VERSION ""

NS_ :

BS_:

BU_:

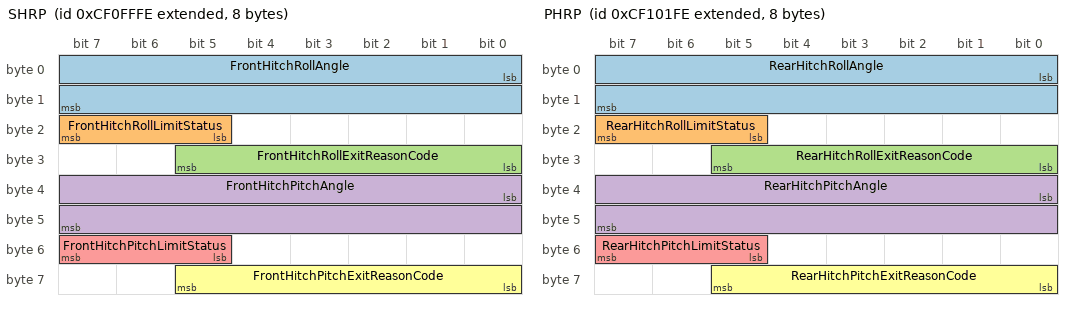
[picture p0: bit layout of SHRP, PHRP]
BO_ 2364604414 SHRP: 8 Vector__XXX
 SG_ FrontHitchRollAngle : 0|16@1+ (0.002,-64) [-64|64.51] "deg" Vector__XXX
 SG_ FrontHitchRollLimitStatus : 21|3@1+ (1,0) [0|7] "" Vector__XXX
 SG_ FrontHitchRollExitReasonCode : 24|6@1+ (1,0) [0|63] "" Vector__XXX
 SG_ FrontHitchPitchAngle : 32|16@1+ (0.002,-64) [-64|64.51] "deg" Vector__XXX
 SG_ FrontHitchPitchLimitStatus : 53|3@1+ (1,0) [0|7] "" Vector__XXX
 SG_ FrontHitchPitchExitReasonCode : 56|6@1+ (1,0) [0|63] "" Vector__XXX

BO_ 2364604926 PHRP: 8 Vector__XXX
 SG_ RearHitchRollAngle : 0|16@1+ (0.002,-64) [-64|64.51] "deg" Vector__XXX
 SG_ RearHitchRollLimitStatus : 21|3@1+ (1,0) [0|7] "" Vector__XXX
 SG_ RearHitchRollExitReasonCode : 24|6@1+ (1,0) [0|63] "" Vector__XXX
 SG_ RearHitchPitchAngle : 32|16@1+ (0.002,-64) [-64|64.51] "deg" Vector__XXX
 SG_ RearHitchPitchLimitStatus : 53|3@1+ (1,0) [0|7] "" Vector__XXX
 SG_ RearHitchPitchExitReasonCode : 56|6@1+ (1,0) [0|63] "" Vector__XXX

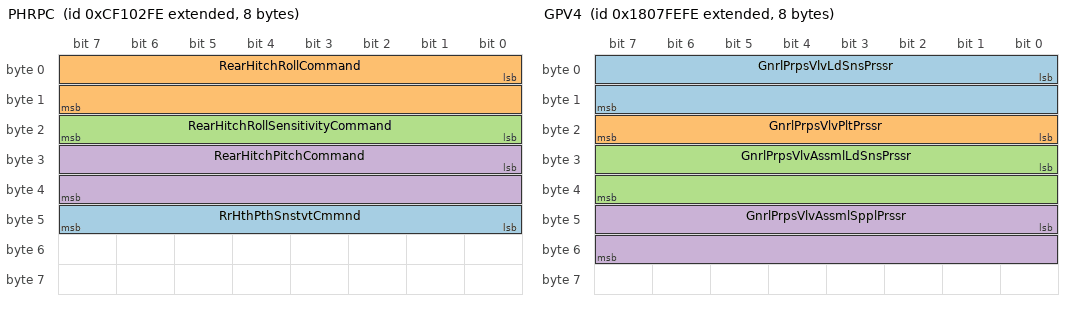
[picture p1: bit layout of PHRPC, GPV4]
BO_ 2364605182 PHRPC: 8 Vector__XXX
 SG_ RrHthPthSnstvtCmmnd : 40|8@1+ (0.4,0) [0|100] "%" Vector__XXX
 SG_ RearHitchRollCommand : 0|16@1+ (0.002,-64) [-64|64.51] "deg" Vector__XXX
 SG_ RearHitchRollSensitivityCommand : 16|8@1+ (0.4,0) [0|100] "%" Vector__XXX
 SG_ RearHitchPitchCommand : 24|16@1+ (0.002,-64) [-64|64.51] "deg" Vector__XXX

BO_ 2365473278 LCMD: 8 Vector__XXX
 SG_ ImplementOemOption1LightCommand : 50|2@1+ (1,0) [0|3] "" Vector__XXX
 SG_ ImplementOemOption2LightCommand : 48|2@1+ (1,0) [0|3] "" Vector__XXX
 SG_ RotatingBeaconLightCommand : 10|2@1+ (1,0) [0|3] "" Vector__XXX
 SG_ TractorFrontFogLightsCommand : 8|2@1+ (1,0) [0|3] "" Vector__XXX
 SG_ TrtrFrntHghMntdWrkLghtsCmmnd : 46|2@1+ (1,0) [0|3] "" Vector__XXX
 SG_ TrtrFrntLwMntdWrkLghtsCmmnd : 44|2@1+ (1,0) [0|3] "" Vector__XXX
 SG_ TrtrUndrsdMntdWrkLghtsCmmnd : 34|2@1+ (1,0) [0|3] "" Vector__XXX
 SG_ DaytimeRunningLightsCommand : 0|2@1+ (1,0) [0|3] "" Vector__XXX
 SG_ AlternateHeadlightsCommand : 2|2@1+ (1,0) [0|3] "" Vector__XXX
 SG_ LowBeamHeadlightsCommand : 4|2@1+ (1,0) [0|3] "" Vector__XXX
 SG_ HighBeamHeadlightsCommand : 6|2@1+ (1,0) [0|3] "" Vector__XXX
 SG_ RightTurnSignalLightsCommand : 12|2@1+ (1,0) [0|3] "" Vector__XXX
 SG_ LeftTurnSignalLightsCommand : 14|2@1+ (1,0) [0|3] "" Vector__XXX
 SG_ BackUpLightsAndAlarmHornCommand : 16|2@1+ (1,0) [0|3] "" Vector__XXX
 SG_ CentreStopLightsCommand : 18|2@1+ (1,0) [0|3] "" Vector__XXX
 SG_ RightStopLightsCommand : 20|2@1+ (1,0) [0|3] "" Vector__XXX
 SG_ LeftStopLightsCommand : 22|2@1+ (1,0) [0|3] "" Vector__XXX
 SG_ ImplementClearanceLightsCommand : 24|2@1+ (1,0) [0|3] "" Vector__XXX
 SG_ TractorClearanceLightsCommand : 26|2@1+ (1,0) [0|3] "" Vector__XXX
 SG_ ImplmntMrkrPstnLghtsCmmnd : 28|2@1+ (1,0) [0|3] "" Vector__XXX
 SG_ TrtrMrkrPstnLghtsCmmnd : 30|2@1+ (1,0) [0|3] "" Vector__XXX
 SG_ RearFogLightsCommand : 32|2@1+ (1,0) [0|3] "" Vector__XXX
 SG_ TrtrRrLwMntdWrkLghtsCmmnd : 36|2@1+ (1,0) [0|3] "" Vector__XXX
 SG_ TrtrRrHghMntdWrkLghtsCmmnd : 38|2@1+ (1,0) [0|3] "" Vector__XXX
 SG_ TrtrSdLwMntdWrkLghtsCmmnd : 40|2@1+ (1,0) [0|3] "" Vector__XXX
 SG_ TrtrSdHghMntdWrkLghtsCmmnd : 42|2@1+ (1,0) [0|3] "" Vector__XXX
 SG_ ImplmntRghtFrwrdWrkLghtsCmmnd : 52|2@1+ (1,0) [0|3] "" Vector__XXX
 SG_ ImplmntLftFrwrdWrkLghtsCmmnd : 54|2@1+ (1,0) [0|3] "" Vector__XXX
 SG_ LghtngDtMssgRqstCmmnd : 56|2@1+ (1,0) [0|3] "" Vector__XXX
 SG_ ImplmntRghtFngWrkLghtsCmmnd : 58|2@1+ (1,0) [0|3] "" Vector__XXX
 SG_ ImplmntLftFngWrkLghtsCmmnd : 60|2@1+ (1,0) [0|3] "" Vector__XXX
 SG_ ImplementRearWorkLightsCommand : 62|2@1+ (1,0) [0|3] "" Vector__XXX

BO_ 2550660862 GPV4: 8 Vector__XXX
 SG_ GnrlPrpsVlvLdSnsPrssr : 0|16@1+ (5,0) [0|321275] "kPa" Vector__XXX
 SG_ GnrlPrpsVlvPltPrssr : 16|8@1+ (16,0) [0|4000] "kPa" Vector__XXX
 SG_ GnrlPrpsVlvAssmlLdSnsPrssr : 24|16@1+ (5,0) [0|321275] "kPa" Vector__XXX
 SG_ GnrlPrpsVlvAssmlSpplPrssr : 40|16@1+ (5,0) [0|321275] "kPa" Vector__XXX

BO_ 2566655742 PHRPS: 8 Vector__XXX
 SG_ RearHitchPitchSensitivity : 8|8@1+ (0.4,0) [0|100] "%" Vector__XXX
 SG_ RearHitchRollSensitivity : 0|8@1+ (0.4,0) [0|100] "%" Vector__XXX

BO_ 2566655998 SHRPS: 8 Vector__XXX
 SG_ FrontHitchRollSensitivity : 0|8@1+ (0.4,0) [0|100] "%" Vector__XXX
 SG_ FrontHitchPitchSensitivity : 8|8@1+ (0.4,0) [0|100] "%" Vector__XXX

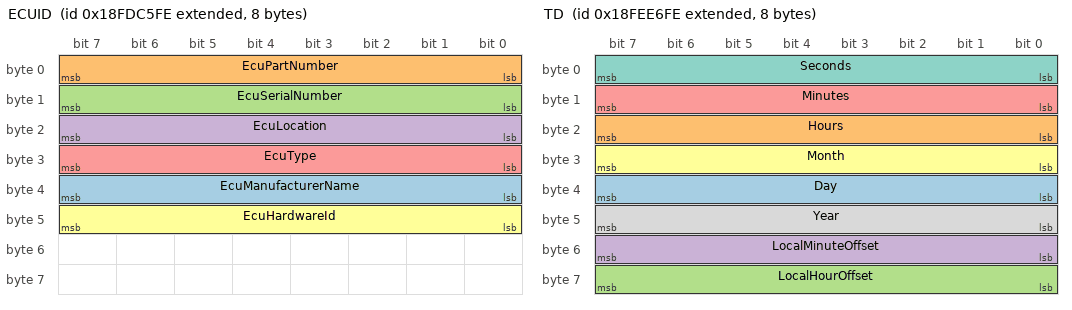
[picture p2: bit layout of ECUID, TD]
BO_ 2566768126 ECUID: 8 Vector__XXX
 SG_ EcuManufacturerName : 32|8@1+ (1,0) [0|255] "ASCII" Vector__XXX
 SG_ EcuPartNumber : 0|8@1+ (1,0) [0|255] "ASCII" Vector__XXX
 SG_ EcuSerialNumber : 8|8@1+ (1,0) [0|255] "ASCII" Vector__XXX
 SG_ EcuLocation : 16|8@1+ (1,0) [0|255] "ASCII" Vector__XXX
 SG_ EcuType : 24|8@1+ (1,0) [0|255] "ASCII" Vector__XXX
 SG_ EcuHardwareId : 40|8@1+ (1,0) [0|255] "ASCII" Vector__XXX

BO_ 2566799614 LD: 8 Vector__XXX
 SG_ ImplementOemOption1Light : 50|2@1+ (1,0) [0|3] "" Vector__XXX
 SG_ ImplementOemOption2Light : 48|2@1+ (1,0) [0|3] "" Vector__XXX
 SG_ LeftTurnSignalLights : 14|2@1+ (1,0) [0|3] "" Vector__XXX
 SG_ RearFogLights : 32|2@1+ (1,0) [0|3] "" Vector__XXX
 SG_ RightTurnSignalLights : 12|2@1+ (1,0) [0|3] "" Vector__XXX
 SG_ RotatingBeaconLight : 10|2@1+ (1,0) [0|3] "" Vector__XXX
 SG_ TractorFrontFogLights : 8|2@1+ (1,0) [0|3] "" Vector__XXX
 SG_ TractorRearLowMountedWorkLights : 36|2@1+ (1,0) [0|3] "" Vector__XXX
 SG_ TractorSideLowMountedWorkLights : 40|2@1+ (1,0) [0|3] "" Vector__XXX
 SG_ TrtrFrntHghMntdWrkLghts : 46|2@1+ (1,0) [0|3] "" Vector__XXX
 SG_ TrtrFrntLwMntdWrkLghts : 44|2@1+ (1,0) [0|3] "" Vector__XXX
 SG_ TrtrRrHghMntdWrkLghts : 38|2@1+ (1,0) [0|3] "" Vector__XXX
 SG_ TrtrSdHghMntdWrkLghts : 42|2@1+ (1,0) [0|3] "" Vector__XXX
 SG_ TrtrUndrsdMntdWrkLghts : 34|2@1+ (1,0) [0|3] "" Vector__XXX
 SG_ DaytimeRunningLights : 0|2@1+ (1,0) [0|3] "" Vector__XXX
 SG_ AlternateHeadlights : 2|2@1+ (1,0) [0|3] "" Vector__XXX
 SG_ LowBeamHeadlights : 4|2@1+ (1,0) [0|3] "" Vector__XXX
 SG_ HighBeamHeadlights : 6|2@1+ (1,0) [0|3] "" Vector__XXX
 SG_ BackUpLightsAndAlarmHorn : 16|2@1+ (1,0) [0|3] "" Vector__XXX
 SG_ CenterStopLights : 18|2@1+ (1,0) [0|3] "" Vector__XXX
 SG_ RightStopLights : 20|2@1+ (1,0) [0|3] "" Vector__XXX
 SG_ LeftStopLights : 22|2@1+ (1,0) [0|3] "" Vector__XXX
 SG_ ImplementClearanceLights : 24|2@1+ (1,0) [0|3] "" Vector__XXX
 SG_ TractorClearanceLights : 26|2@1+ (1,0) [0|3] "" Vector__XXX
 SG_ ImplementMarkerPositionLights : 28|2@1+ (1,0) [0|3] "" Vector__XXX
 SG_ TractorMarkerPositionLights : 30|2@1+ (1,0) [0|3] "" Vector__XXX
 SG_ ImplementRightForwardWorkLights : 52|2@1+ (1,0) [0|3] "" Vector__XXX
 SG_ ImplementLeftForwardWorkLights : 54|2@1+ (1,0) [0|3] "" Vector__XXX
 SG_ ImplementRightFacingWorkLights : 58|2@1+ (1,0) [0|3] "" Vector__XXX
 SG_ ImplementLeftFacingWorkLights : 60|2@1+ (1,0) [0|3] "" Vector__XXX
 SG_ ImplementRearWorkLights : 62|2@1+ (1,0) [0|3] "" Vector__XXX

BO_ 2566839038 SOFT: 8 Vector__XXX
 SG_ NmrOfSftwrIdntftnFlds : 0|8@1+ (1,0) [0|250] "step" Vector__XXX
 SG_ SoftwareIdentification : 8|8@1+ (1,0) [0|255] "ASCII" Vector__XXX

BO_ 2566842110 TD: 8 Vector__XXX
 SG_ Day : 32|8@1+ (0.25,0) [0.25|62.5] "days" Vector__XXX
 SG_ Hours : 16|8@1+ (1,0) [0|250] "h" Vector__XXX
 SG_ LocalHourOffset : 56|8@1+ (1,-125) [-23|125] "h" Vector__XXX
 SG_ LocalMinuteOffset : 48|8@1+ (1,-125) [-59|125] "min" Vector__XXX
 SG_ Minutes : 8|8@1+ (1,0) [0|250] "min" Vector__XXX
 SG_ Month : 24|8@1+ (1,0) [1|250] "month" Vector__XXX
 SG_ Seconds : 0|8@1+ (0.25,0) [0|62.5] "s" Vector__XXX
 SG_ Year : 40|8@1+ (1,1985) [1985|2235] "year" Vector__XXX

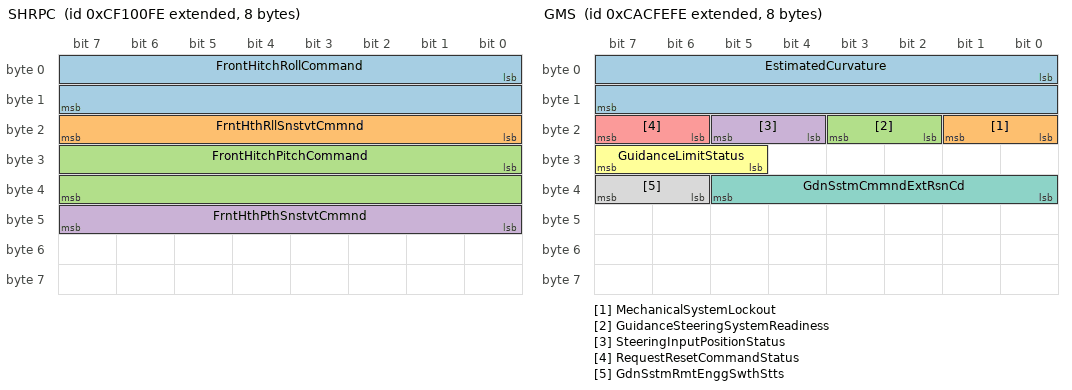
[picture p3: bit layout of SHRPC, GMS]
BO_ 2364604670 SHRPC: 8 Vector__XXX
 SG_ FrontHitchRollCommand : 0|16@1+ (0.002,-64) [-64|64.51] "deg" Vector__XXX
 SG_ FrntHthRllSnstvtCmmnd : 16|8@1+ (0.4,0) [0|100] "%" Vector__XXX
 SG_ FrontHitchPitchCommand : 24|16@1+ (0.002,-64) [-64|64.51] "deg" Vector__XXX
 SG_ FrntHthPthSnstvtCmmnd : 40|8@1+ (0.4,0) [0|100] "%" Vector__XXX

BO_ 2360147710 GMS: 8 Vector__XXX
 SG_ EstimatedCurvature : 0|16@1+ (0.25,-8032) [-8032|8031.72] "km-1" Vector__XXX
 SG_ MechanicalSystemLockout : 16|2@1+ (1,0) [0|3] "" Vector__XXX
 SG_ GuidanceSteeringSystemReadiness : 18|2@1+ (1,0) [0|3] "" Vector__XXX
 SG_ SteeringInputPositionStatus : 20|2@1+ (1,0) [0|3] "" Vector__XXX
 SG_ RequestResetCommandStatus : 22|2@1+ (1,0) [0|3] "" Vector__XXX
 SG_ GuidanceLimitStatus : 29|3@1+ (1,0) [0|7] "" Vector__XXX
 SG_ GdnSstmCmmndExtRsnCd : 32|6@1+ (1,0) [0|63] "" Vector__XXX
 SG_ GdnSstmRmtEnggSwthStts : 38|2@1+ (1,0) [0|3] "" Vector__XXX

BO_ 2360213246 GSC: 8 Vector__XXX
 SG_ CurvatureCommand : 0|16@1+ (0.25,-8032) [-8032|8031.72] "km-1" Vector__XXX
 SG_ CurvatureCommandStatus : 16|2@1+ (1,0) [0|3] "" Vector__XXX

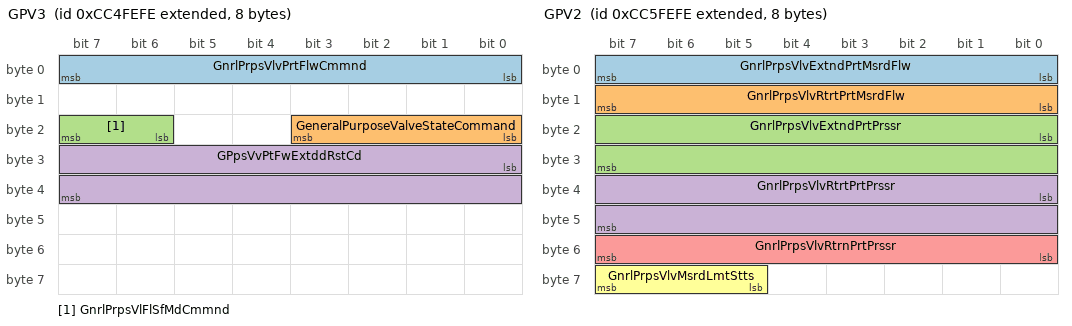
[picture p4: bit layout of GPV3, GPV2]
BO_ 2361720574 GPV3: 8 Vector__XXX
 SG_ GnrlPrpsVlvPrtFlwCmmnd : 0|8@1+ (0.4,0) [0|100] "%" Vector__XXX
 SG_ GeneralPurposeValveStateCommand : 16|4@1+ (1,0) [0|15] "" Vector__XXX
 SG_ GnrlPrpsVlFlSfMdCmmnd : 22|2@1+ (1,0) [0|3] "" Vector__XXX
 SG_ GPpsVvPtFwExtddRstCd : 24|16@1+ (0.0015625,0) [0|100.3984375] "%" Vector__XXX

BO_ 2361786110 GPV2: 8 Vector__XXX
 SG_ GnrlPrpsVlvExtndPrtMsrdFlw : 0|8@1+ (1,-125) [-125|125] "%" Vector__XXX
 SG_ GnrlPrpsVlvRtrtPrtMsrdFlw : 8|8@1+ (1,-125) [-125|125] "%" Vector__XXX
 SG_ GnrlPrpsVlvExtndPrtPrssr : 16|16@1+ (5,0) [0|321275] "kPa" Vector__XXX
 SG_ GnrlPrpsVlvRtrtPrtPrssr : 32|16@1+ (5,0) [0|321275] "kPa" Vector__XXX
 SG_ GnrlPrpsVlvRtrnPrtPrssr : 48|8@1+ (16,0) [0|4000] "kPa" Vector__XXX
 SG_ GnrlPrpsVlvMsrdLmtStts : 61|3@1+ (1,0) [0|7] "" Vector__XXX

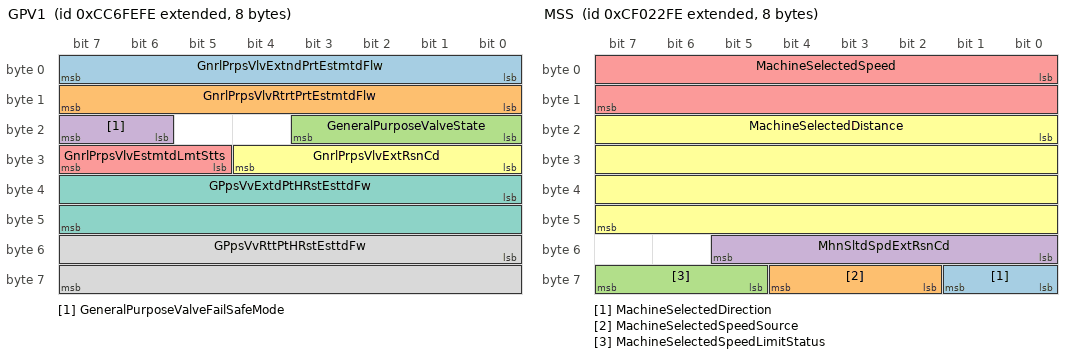
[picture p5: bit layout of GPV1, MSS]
BO_ 2361851646 GPV1: 8 Vector__XXX
 SG_ GnrlPrpsVlvExtndPrtEstmtdFlw : 0|8@1+ (1,-125) [-125|125] "%" Vector__XXX
 SG_ GnrlPrpsVlvRtrtPrtEstmtdFlw : 8|8@1+ (1,-125) [-125|125] "%" Vector__XXX
 SG_ GeneralPurposeValveState : 16|4@1+ (1,0) [0|15] "" Vector__XXX
 SG_ GeneralPurposeValveFailSafeMode : 22|2@1+ (1,0) [0|3] "" Vector__XXX
 SG_ GnrlPrpsVlvEstmtdLmtStts : 29|3@1+ (1,0) [0|7] "" Vector__XXX
 SG_ GnrlPrpsVlvExtRsnCd : 24|5@1+ (1,0) [0|31] "" Vector__XXX
 SG_ GPpsVvExtdPtHRstEsttdFw : 32|16@1+ (0.004,-125) [-125|132.02] "%" Vector__XXX
 SG_ GPpsVvRttPtHRstEsttdFw : 48|16@1+ (0.004,-125) [-125|132.02] "%" Vector__XXX

BO_ 2563571454 REQRR: 8 Vector__XXX
 SG_ PgnOfTheRequest1 : 0|24@1+ (1,0) [0|16777215] "" Vector__XXX
 SG_ RepetitionRateCommand : 24|16@1+ (1,0) [0|64255] "ms" Vector__XXX

BO_ 2362507006 CL: 8 Vector__XXX
 SG_ BkgrndIllmntnLvlCmmnd : 0|8@1+ (0.4,0) [0|100] "%" Vector__XXX

BO_ 2364547838 MSS: 8 Vector__XXX
 SG_ MachineSelectedDirection : 56|2@1+ (1,0) [0|3] "" Vector__XXX
 SG_ MachineSelectedSpeedSource : 58|3@1+ (1,0) [0|7] "" Vector__XXX
 SG_ MachineSelectedSpeedLimitStatus : 61|3@1+ (1,0) [0|7] "" Vector__XXX
 SG_ MhnSltdSpdExtRsnCd : 48|6@1+ (1,0) [0|63] "" Vector__XXX
 SG_ MachineSelectedSpeed : 0|16@1+ (0.001,0) [0|64.255] "m/s" Vector__XXX
 SG_ MachineSelectedDistance : 16|32@1+ (0.001,0) [0|4211081.215] "m" Vector__XXX

BO_ 2364597502 HRTBTM: 8 Vector__XXX
 SG_ HeartbeatSequenceNumber : 0|8@1+ (1,0) [0|255] "count" Vector__XXX

BO_ 2364620542 FHYC: 8 Vector__XXX
 SG_ FrontHitchYawCommand : 0|16@1+ (0.0078125,-200) [-200|301.9921875] "deg" Vector__XXX

BO_ 2364620798 RHYC: 8 Vector__XXX
 SG_ RearHitchYawCommand : 0|16@1+ (0.0078125,-200) [-200|301.9921875] "deg" Vector__XXX

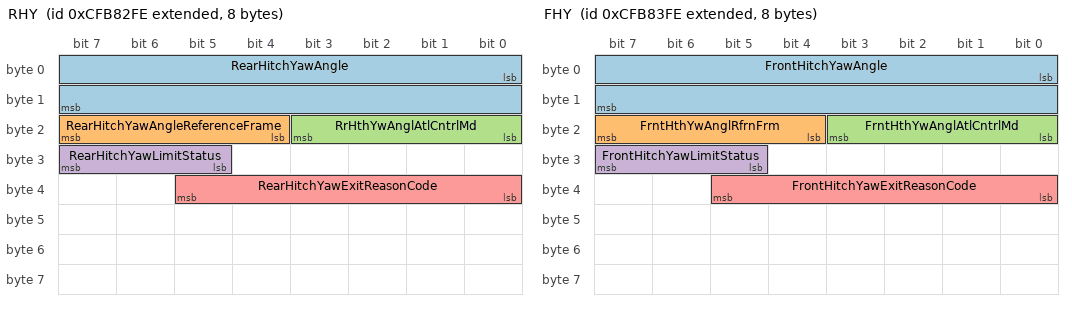
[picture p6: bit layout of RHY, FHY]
BO_ 2365293310 RHY: 8 Vector__XXX
 SG_ RearHitchYawAngle : 0|16@1+ (0.0078125,-200) [-200|301.9921875] "deg" Vector__XXX
 SG_ RearHitchYawAngleReferenceFrame : 20|4@1+ (1,0) [0|15] "" Vector__XXX
 SG_ RrHthYwAnglAtlCntrlMd : 16|4@1+ (1,0) [0|15] "" Vector__XXX
 SG_ RearHitchYawLimitStatus : 29|3@1+ (1,0) [0|7] "" Vector__XXX
 SG_ RearHitchYawExitReasonCode : 32|6@1+ (1,0) [0|63] "" Vector__XXX

BO_ 2365293566 FHY: 8 Vector__XXX
 SG_ FrontHitchYawAngle : 0|16@1+ (0.0078125,-200) [-200|301.9921875] "deg" Vector__XXX
 SG_ FrntHthYwAnglRfrnFrm : 20|4@1+ (1,0) [0|15] "" Vector__XXX
 SG_ FrntHthYwAnglAtlCntrlMd : 16|4@1+ (1,0) [0|15] "" Vector__XXX
 SG_ FrontHitchYawLimitStatus : 29|3@1+ (1,0) [0|7] "" Vector__XXX
 SG_ FrontHitchYawExitReasonCode : 32|6@1+ (1,0) [0|63] "" Vector__XXX

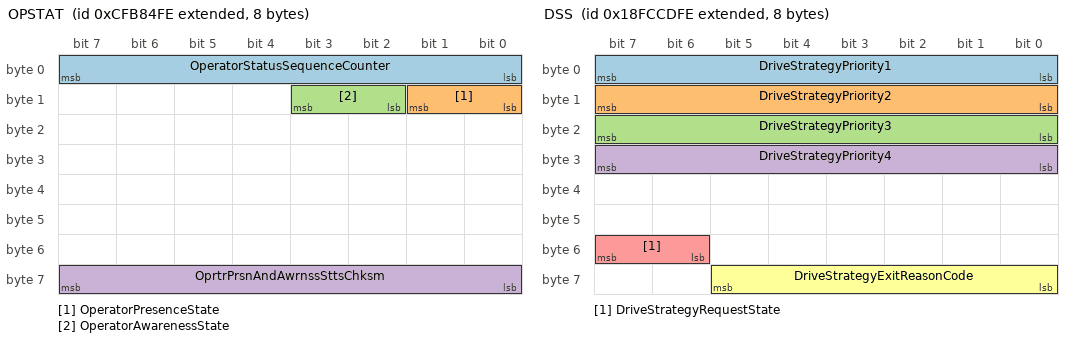
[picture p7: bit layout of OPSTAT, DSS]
BO_ 2365293822 OPSTAT: 8 Vector__XXX
 SG_ OperatorStatusSequenceCounter : 0|8@1+ (1,0) [0|255] "" Vector__XXX
 SG_ OperatorPresenceState : 8|2@1+ (1,0) [0|3] "" Vector__XXX
 SG_ OperatorAwarenessState : 10|2@1+ (1,0) [0|3] "" Vector__XXX
 SG_ OprtrPrsnAndAwrnssSttsChksm : 56|8@1+ (1,0) [0|255] "" Vector__XXX

BO_ 2566704638 DSS: 8 Vector__XXX
 SG_ DriveStrategyPriority1 : 0|8@1+ (1,0) [0|255] "" Vector__XXX
 SG_ DriveStrategyPriority2 : 8|8@1+ (1,0) [0|255] "" Vector__XXX
 SG_ DriveStrategyPriority3 : 16|8@1+ (1,0) [0|255] "" Vector__XXX
 SG_ DriveStrategyPriority4 : 24|8@1+ (1,0) [0|255] "" Vector__XXX
 SG_ DriveStrategyRequestState : 54|2@1+ (1,0) [0|3] "" Vector__XXX
 SG_ DriveStrategyExitReasonCode : 56|6@1+ (1,0) [0|63] "" Vector__XXX

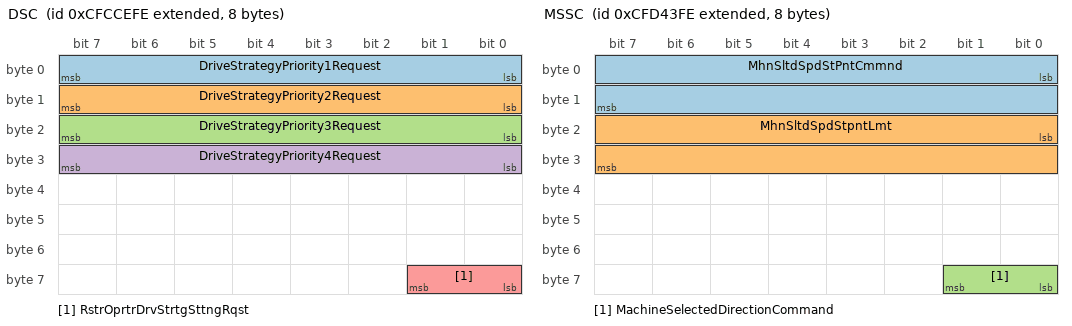
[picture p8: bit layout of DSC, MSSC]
BO_ 2365378302 DSC: 8 Vector__XXX
 SG_ DriveStrategyPriority1Request : 0|8@1+ (1,0) [0|255] "" Vector__XXX
 SG_ DriveStrategyPriority2Request : 8|8@1+ (1,0) [0|255] "" Vector__XXX
 SG_ DriveStrategyPriority3Request : 16|8@1+ (1,0) [0|255] "" Vector__XXX
 SG_ DriveStrategyPriority4Request : 24|8@1+ (1,0) [0|255] "" Vector__XXX
 SG_ RstrOprtrDrvStrtgSttngRqst : 56|2@1+ (1,0) [0|3] "" Vector__XXX

BO_ 2365391614 AISO: 8 Vector__XXX
 SG_ StopAllImplementOperations : 56|2@1+ (1,0) [0|3] "" Vector__XXX
 SG_ StpAllImplmntOprtnsTrnstnNmr : 48|8@1+ (1,0) [0|255] "" Vector__XXX

BO_ 2365391870 IOS: 8 Vector__XXX
 SG_ ImplementOperatingStateCommand : 56|2@1+ (1,0) [0|3] "" Vector__XXX

BO_ 2566730494 ECUDP: 8 Vector__XXX
 SG_ DgnstPrtlIdntftn : 0|8@1+ (1,0) [0|255] "" Vector__XXX

BO_ 2566734590 ICC: 8 Vector__XXX
 SG_ IssCmplnTstPrtlPltnYr : 0|6@1+ (1,2000) [2000|2061] "years" Vector__XXX
 SG_ IssCmplnCrtftnLrtrId : 13|11@1+ (1,0) [0|2047] "" Vector__XXX
 SG_ IssCmplnCrtftnTpMnmmCf : 31|1@1+ (1,0) [0|1] "" Vector__XXX
 SG_ IssCmplnCrtftnTpTClss1 : 30|1@1+ (1,0) [0|1] "" Vector__XXX
 SG_ IssCmplnCrtftnTpTClss2 : 29|1@1+ (1,0) [0|1] "" Vector__XXX
 SG_ IssCmplnCrtftnTpTClss3 : 28|1@1+ (1,0) [0|1] "" Vector__XXX
 SG_ IssCmplnCrtftnTpClss3E : 27|1@1+ (1,0) [0|1] "" Vector__XXX
 SG_ IssCmplnCrtftnTpVrtlTrmnl : 26|1@1+ (1,0) [0|1] "" Vector__XXX
 SG_ IssCmplnCrtftnTpVtWrkngStMstr : 25|1@1+ (1,0) [0|1] "" Vector__XXX
 SG_ IssCmplnCrtftnTpVtWrkngStMmr : 24|1@1+ (1,0) [0|1] "" Vector__XXX
 SG_ IssCmplnCrtftnTpTskCntrllr : 39|1@1+ (1,0) [0|1] "" Vector__XXX
 SG_ IssCmplnCrtftnTpTWrkngStMstr : 38|1@1+ (1,0) [0|1] "" Vector__XXX
 SG_ IssCmplnCrtftnTpTWrkngStMmr : 37|1@1+ (1,0) [0|1] "" Vector__XXX
 SG_ IssCmplnCrtftnTpFlSrvr : 36|1@1+ (1,0) [0|1] "" Vector__XXX
 SG_ IssCmplnCrtftnTpGpsRvr : 35|1@1+ (1,0) [0|1] "" Vector__XXX
 SG_ IssCmplnCrtftnRfrnNmr : 48|16@1+ (1,0) [0|65535] "count" Vector__XXX
 SG_ IssCmplnCrtftnMssgRvsn : 47|1@1+ (1,0) [0|1] "" Vector__XXX

BO_ 2365408254 MSSC: 8 Vector__XXX
 SG_ MhnSltdSpdStPntCmmnd : 0|16@1+ (0.001,0) [0|64.255] "m/s" Vector__XXX
 SG_ MhnSltdSpdStpntLmt : 16|16@1+ (0.001,0) [0|64.255] "m/s" Vector__XXX
 SG_ MachineSelectedDirectionCommand : 56|2@1+ (1,0) [0|3] "" Vector__XXX

BO_ 2365458686 RTF: 8 Vector__XXX
 SG_ MachineSelectedSpeed : 34|1@1+ (1,0) [0|1] "" Vector__XXX
 SG_ SpeedInformationEngineSpeed : 0|1@1+ (1,0) [0|1] "" Vector__XXX
 SG_ SpdInfrmtnGrndBsdSpd1 : 1|1@1+ (1,0) [0|1] "" Vector__XXX
 SG_ SpeedInformationWheelBasedSpeed1 : 2|1@1+ (1,0) [0|1] "" Vector__XXX
 SG_ PowerManagementMaintainPower : 3|1@1+ (1,0) [0|1] "" Vector__XXX
 SG_ PwrMngmntMxmmTmTrtrPwr : 4|1@1+ (1,0) [0|1] "" Vector__XXX
 SG_ PowerManagementKeySwitch : 5|1@1+ (1,0) [0|1] "" Vector__XXX
 SG_ TractorEcuClassRequest : 6|2@1+ (1,0) [0|3] "" Vector__XXX
 SG_ LnggCmmndStrgInTrtrE : 10|1@1+ (1,0) [0|1] "" Vector__XXX
 SG_ LghtngMnmlStAsExstngTrlrCnntr : 11|1@1+ (1,0) [0|1] "" Vector__XXX
 SG_ PtInfrmtnRrShftEnggmnt : 12|1@1+ (1,0) [0|1] "" Vector__XXX
 SG_ PtoInformationRearShaftSpeed : 13|1@1+ (1,0) [0|1] "" Vector__XXX
 SG_ HitchInformationRearInWork : 14|1@1+ (1,0) [0|1] "" Vector__XXX
 SG_ HitchInformationRearPosition : 15|1@1+ (1,0) [0|1] "" Vector__XXX
 SG_ EstmtdOrMsrdAxlrVlvStts : 16|1@1+ (1,0) [0|1] "" Vector__XXX
 SG_ LghtngFllImplmntLghtngMssgSt : 17|1@1+ (1,0) [0|1] "" Vector__XXX
 SG_ AddtnlHthPrmtrsRrDrft : 18|1@1+ (1,0) [0|1] "" Vector__XXX
 SG_ SpdAndDstnWhlBsdDrtn : 19|1@1+ (1,0) [0|1] "" Vector__XXX
 SG_ SpdAndDstnWhlBsdDstn : 20|1@1+ (1,0) [0|1] "" Vector__XXX
 SG_ SpdAndDstnGrndBsdDrtn : 21|1@1+ (1,0) [0|1] "" Vector__XXX
 SG_ SpdAndDstnGrndBsdDstn : 22|1@1+ (1,0) [0|1] "" Vector__XXX
 SG_ TimeDate : 23|1@1+ (1,0) [0|1] "" Vector__XXX
 SG_ PtCmmndsRrPtMdGrCmmnd : 26|1@1+ (1,0) [0|1] "" Vector__XXX
 SG_ LimitRequestStatusReporting : 27|1@1+ (1,0) [0|1] "" Vector__XXX
 SG_ AuxiliaryValveCommands : 28|1@1+ (1,0) [0|1] "" Vector__XXX
 SG_ PtCmmndsRrPtEnggmntCmmnd : 29|1@1+ (1,0) [0|1] "" Vector__XXX
 SG_ PtoCommandsRearPtoSpeedCommand : 30|1@1+ (1,0) [0|1] "" Vector__XXX
 SG_ HitchCommandsRearHitchPosition : 31|1@1+ (1,0) [0|1] "" Vector__XXX
 SG_ DirectionControl : 32|1@1+ (1,0) [0|1] "" Vector__XXX
 SG_ MachineSelectedSpeedControl : 33|1@1+ (1,0) [0|1] "" Vector__XXX
 SG_ OperatorExternalLightControls : 35|1@1+ (1,0) [0|1] "" Vector__XXX
 SG_ NvgtnlPsdRngNsSttsts : 37|1@1+ (1,0) [0|1] "" Vector__XXX
 SG_ NavigationalSystemPositionData : 38|1@1+ (1,0) [0|1] "" Vector__XXX
 SG_ NvgtnlSstmHghOtptPstn : 39|1@1+ (1,0) [0|1] "" Vector__XXX
 SG_ PtCmmndsFrntPtEnggmntCmmnd : 40|1@1+ (1,0) [0|1] "" Vector__XXX
 SG_ PtoCommandsFrontPtoSpeedCommand : 41|1@1+ (1,0) [0|1] "" Vector__XXX
 SG_ HitchCommandsFrontHitchPosition : 42|1@1+ (1,0) [0|1] "" Vector__XXX
 SG_ AddtnlHthPrmtrsFrntDrft : 43|1@1+ (1,0) [0|1] "" Vector__XXX
 SG_ PtInfrmtnFrntShftEnggmnt : 44|1@1+ (1,0) [0|1] "" Vector__XXX
 SG_ PtoInformationFrontShaftSpeed : 45|1@1+ (1,0) [0|1] "" Vector__XXX
 SG_ HitchInformationFrontInWork : 46|1@1+ (1,0) [0|1] "" Vector__XXX
 SG_ HitchInformationFrontPosition : 47|1@1+ (1,0) [0|1] "" Vector__XXX
 SG_ DriveStrategyStatusAndCommands : 48|1@1+ (1,0) [0|1] "" Vector__XXX
 SG_ ExtrnlGdnSttsAndCmmnds : 49|1@1+ (1,0) [0|1] "" Vector__XXX
 SG_ PtCmmndsFrntPtMdGrCmmnd : 55|1@1+ (1,0) [0|1] "" Vector__XXX
 SG_ TrtrFltRsrvdBtIndtr : 56|1@1+ (1,0) [0|1] "" Vector__XXX

BO_ 2365458942 TFR: 8 Vector__XXX
 SG_ MachineSelectedSpeed : 34|1@1+ (1,0) [0|1] "" Vector__XXX
 SG_ SpeedInformationEngineSpeed : 0|1@1+ (1,0) [0|1] "" Vector__XXX
 SG_ PowerManagementMaintainPower : 3|1@1+ (1,0) [0|1] "" Vector__XXX
 SG_ PwrMngmntMxmmTmTrtrPwr : 4|1@1+ (1,0) [0|1] "" Vector__XXX
 SG_ PowerManagementKeySwitch : 5|1@1+ (1,0) [0|1] "" Vector__XXX
 SG_ LnggCmmndStrgInTrtrE : 10|1@1+ (1,0) [0|1] "" Vector__XXX
 SG_ LghtngMnmlStAsExstngTrlrCnntr : 11|1@1+ (1,0) [0|1] "" Vector__XXX
 SG_ PtInfrmtnRrShftEnggmnt : 12|1@1+ (1,0) [0|1] "" Vector__XXX
 SG_ PtoInformationRearShaftSpeed : 13|1@1+ (1,0) [0|1] "" Vector__XXX
 SG_ HitchInformationRearInWork : 14|1@1+ (1,0) [0|1] "" Vector__XXX
 SG_ HitchInformationRearPosition : 15|1@1+ (1,0) [0|1] "" Vector__XXX
 SG_ EstmtdOrMsrdAxlrVlvStts : 16|1@1+ (1,0) [0|1] "" Vector__XXX
 SG_ LghtngFllImplmntLghtngMssgSt : 17|1@1+ (1,0) [0|1] "" Vector__XXX
 SG_ AddtnlHthPrmtrsRrDrft : 18|1@1+ (1,0) [0|1] "" Vector__XXX
 SG_ SpdAndDstnWhlBsdDrtn : 19|1@1+ (1,0) [0|1] "" Vector__XXX
 SG_ SpdAndDstnWhlBsdDstn : 20|1@1+ (1,0) [0|1] "" Vector__XXX
 SG_ SpdAndDstnGrndBsdDrtn : 21|1@1+ (1,0) [0|1] "" Vector__XXX
 SG_ SpdAndDstnGrndBsdDstn : 22|1@1+ (1,0) [0|1] "" Vector__XXX
 SG_ TimeDate : 23|1@1+ (1,0) [0|1] "" Vector__XXX
 SG_ PtCmmndsRrPtMdGrCmmnd : 26|1@1+ (1,0) [0|1] "" Vector__XXX
 SG_ AuxiliaryValveCommands : 28|1@1+ (1,0) [0|1] "" Vector__XXX
 SG_ PtCmmndsRrPtEnggmntCmmnd : 29|1@1+ (1,0) [0|1] "" Vector__XXX
 SG_ PtoCommandsRearPtoSpeedCommand : 30|1@1+ (1,0) [0|1] "" Vector__XXX
 SG_ HitchCommandsRearHitchPosition : 31|1@1+ (1,0) [0|1] "" Vector__XXX
 SG_ DirectionControl : 32|1@1+ (1,0) [0|1] "" Vector__XXX
 SG_ MachineSelectedSpeedControl : 33|1@1+ (1,0) [0|1] "" Vector__XXX
 SG_ OperatorExternalLightControls : 35|1@1+ (1,0) [0|1] "" Vector__XXX
 SG_ NvgtnlPsdRngNsSttsts : 37|1@1+ (1,0) [0|1] "" Vector__XXX
 SG_ NavigationalSystemPositionData : 38|1@1+ (1,0) [0|1] "" Vector__XXX
 SG_ NvgtnlSstmHghOtptPstn : 39|1@1+ (1,0) [0|1] "" Vector__XXX
 SG_ PtCmmndsFrntPtEnggmntCmmnd : 40|1@1+ (1,0) [0|1] "" Vector__XXX
 SG_ PtoCommandsFrontPtoSpeedCommand : 41|1@1+ (1,0) [0|1] "" Vector__XXX
 SG_ HitchCommandsFrontHitchPosition : 42|1@1+ (1,0) [0|1] "" Vector__XXX
 SG_ AddtnlHthPrmtrsFrntDrft : 43|1@1+ (1,0) [0|1] "" Vector__XXX
 SG_ PtInfrmtnFrntShftEnggmnt : 44|1@1+ (1,0) [0|1] "" Vector__XXX
 SG_ PtoInformationFrontShaftSpeed : 45|1@1+ (1,0) [0|1] "" Vector__XXX
 SG_ HitchInformationFrontInWork : 46|1@1+ (1,0) [0|1] "" Vector__XXX
 SG_ HitchInformationFrontPosition : 47|1@1+ (1,0) [0|1] "" Vector__XXX
 SG_ DriveStrategyStatusAndCommands : 48|1@1+ (1,0) [0|1] "" Vector__XXX
 SG_ ExtrnlGdnSttsAndCmmnds : 49|1@1+ (1,0) [0|1] "" Vector__XXX
 SG_ PtCmmndsFrntPtMdGrCmmnd : 55|1@1+ (1,0) [0|1] "" Vector__XXX
 SG_ TrtrFltRsrvdBtIndtr : 56|1@1+ (1,0) [0|1] "" Vector__XXX
 SG_ SpdInfrmtnGrndBsdSpd2 : 1|1@1+ (1,0) [0|1] "" Vector__XXX
 SG_ SpeedInformationWheelBasedSpeed2 : 2|1@1+ (1,0) [0|1] "" Vector__XXX
 SG_ TractorEcuClassResponse : 6|2@1+ (1,0) [0|3] "" Vector__XXX
 SG_ TrtrFltRspnsLmtRqstSttsRprtng : 27|1@1+ (1,0) [0|1] "" Vector__XXX

BO_ 2365459454 IRC: 8 Vector__XXX
 SG_ TrtrCntrlMdCmmndNmr1 : 3|5@1+ (1,0) [0|31] "" Vector__XXX
 SG_ TrtrCntrlMdCmmndNmr2 : 11|5@1+ (1,0) [0|31] "" Vector__XXX

BO_ 2633895166 WSMEM: 8 Vector__XXX
 SG_ NameOfWorkingSetMember : 0|64@1+ (1,0) [0|18446744073709551615] "" Vector__XXX

BO_ 2633895422 WSMSTR: 8 Vector__XXX
 SG_ NumberOfMembersInWorkingSet : 0|8@1+ (1,0) [0|250] "" Vector__XXX

BO_ 2566786814 RESRR: 8 Vector__XXX
 SG_ PgnOfTheRequest2 : 0|24@1+ (1,0) [0|16777215] "" Vector__XXX
 SG_ RepetitionRate : 24|16@1+ (1,0) [0|64255] "ms" Vector__XXX

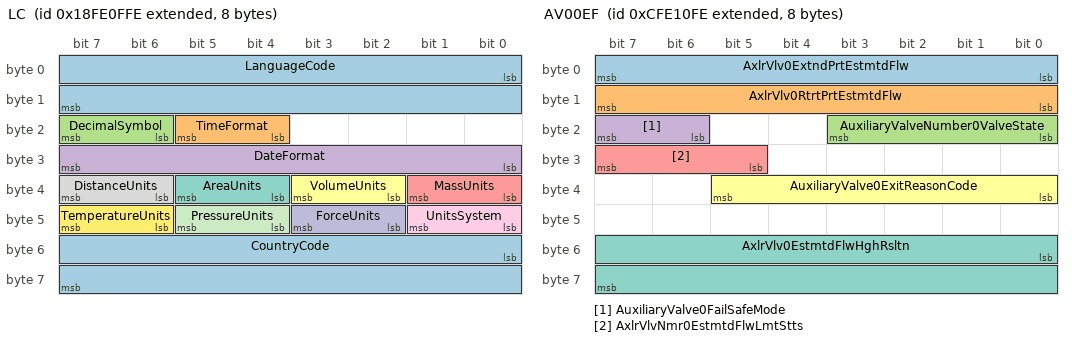
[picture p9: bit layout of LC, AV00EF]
BO_ 2566787070 LC: 8 Vector__XXX
 SG_ LanguageCode : 0|16@1+ (1,0) [97|255] "" Vector__XXX
 SG_ TimeFormat : 20|2@1+ (1,0) [0|3] "" Vector__XXX
 SG_ DecimalSymbol : 22|2@1+ (1,0) [0|3] "" Vector__XXX
 SG_ DateFormat : 24|8@1+ (1,0) [0|255] "binary" Vector__XXX
 SG_ MassUnits : 32|2@1+ (1,0) [0|3] "" Vector__XXX
 SG_ VolumeUnits : 34|2@1+ (1,0) [0|3] "" Vector__XXX
 SG_ AreaUnits : 36|2@1+ (1,0) [0|3] "" Vector__XXX
 SG_ DistanceUnits : 38|2@1+ (1,0) [0|3] "" Vector__XXX
 SG_ UnitsSystem : 40|2@1+ (1,0) [0|3] "" Vector__XXX
 SG_ ForceUnits : 42|2@1+ (1,0) [0|3] "" Vector__XXX
 SG_ PressureUnits : 44|2@1+ (1,0) [0|3] "" Vector__XXX
 SG_ TemperatureUnits : 46|2@1+ (1,0) [0|3] "" Vector__XXX
 SG_ CountryCode : 48|16@1+ (1,0) [65|255] "" Vector__XXX

BO_ 2365460734 AV00EF: 8 Vector__XXX
 SG_ AxlrVlv0ExtndPrtEstmtdFlw : 0|8@1+ (1,-125) [-125|125] "%" Vector__XXX
 SG_ AxlrVlv0RtrtPrtEstmtdFlw : 8|8@1+ (1,-125) [-125|125] "%" Vector__XXX
 SG_ AuxiliaryValveNumber0ValveState : 16|4@1+ (1,0) [0|15] "" Vector__XXX
 SG_ AuxiliaryValve0FailSafeMode : 22|2@1+ (1,0) [0|3] "" Vector__XXX
 SG_ AxlrVlvNmr0EstmtdFlwLmtStts : 29|3@1+ (1,0) [0|7] "" Vector__XXX
 SG_ AuxiliaryValve0ExitReasonCode : 32|6@1+ (1,0) [0|63] "" Vector__XXX
 SG_ AxlrVlv0EstmtdFlwHghRsltn : 48|16@1+ (0.004,-125) [-125|132.02] "%" Vector__XXX

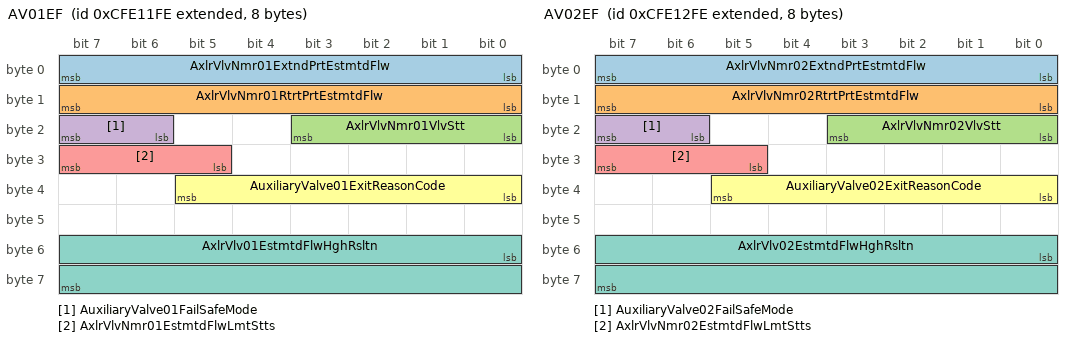
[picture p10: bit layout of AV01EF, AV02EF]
BO_ 2365460990 AV01EF: 8 Vector__XXX
 SG_ AxlrVlvNmr01ExtndPrtEstmtdFlw : 0|8@1+ (1,-125) [-125|125] "%" Vector__XXX
 SG_ AxlrVlvNmr01RtrtPrtEstmtdFlw : 8|8@1+ (1,-125) [-125|125] "%" Vector__XXX
 SG_ AxlrVlvNmr01VlvStt : 16|4@1+ (1,0) [0|15] "" Vector__XXX
 SG_ AuxiliaryValve01FailSafeMode : 22|2@1+ (1,0) [0|3] "" Vector__XXX
 SG_ AxlrVlvNmr01EstmtdFlwLmtStts : 29|3@1+ (1,0) [0|7] "" Vector__XXX
 SG_ AuxiliaryValve01ExitReasonCode : 32|6@1+ (1,0) [0|63] "" Vector__XXX
 SG_ AxlrVlv01EstmtdFlwHghRsltn : 48|16@1+ (0.004,-125) [-125|132.02] "%" Vector__XXX

BO_ 2365461246 AV02EF: 8 Vector__XXX
 SG_ AxlrVlvNmr02ExtndPrtEstmtdFlw : 0|8@1+ (1,-125) [-125|125] "%" Vector__XXX
 SG_ AxlrVlvNmr02RtrtPrtEstmtdFlw : 8|8@1+ (1,-125) [-125|125] "%" Vector__XXX
 SG_ AxlrVlvNmr02VlvStt : 16|4@1+ (1,0) [0|15] "" Vector__XXX
 SG_ AuxiliaryValve02FailSafeMode : 22|2@1+ (1,0) [0|3] "" Vector__XXX
 SG_ AxlrVlvNmr02EstmtdFlwLmtStts : 29|3@1+ (1,0) [0|7] "" Vector__XXX
 SG_ AuxiliaryValve02ExitReasonCode : 32|6@1+ (1,0) [0|63] "" Vector__XXX
 SG_ AxlrVlv02EstmtdFlwHghRsltn : 48|16@1+ (0.004,-125) [-125|132.02] "%" Vector__XXX

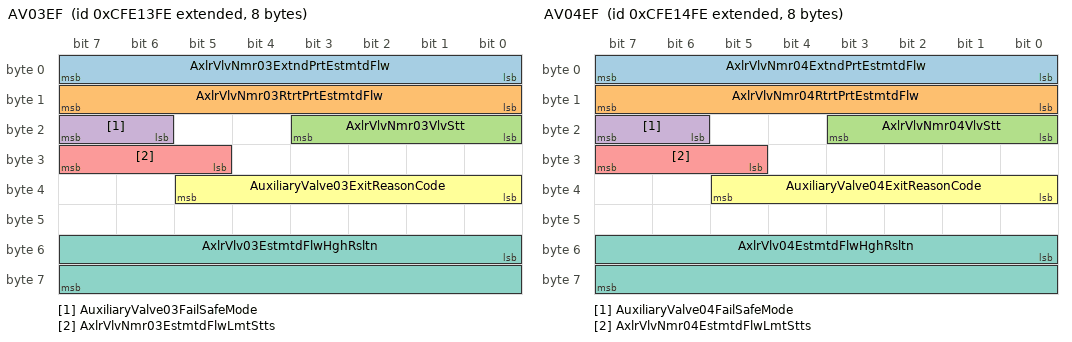
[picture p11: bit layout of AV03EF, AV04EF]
BO_ 2365461502 AV03EF: 8 Vector__XXX
 SG_ AxlrVlvNmr03ExtndPrtEstmtdFlw : 0|8@1+ (1,-125) [-125|125] "%" Vector__XXX
 SG_ AxlrVlvNmr03RtrtPrtEstmtdFlw : 8|8@1+ (1,-125) [-125|125] "%" Vector__XXX
 SG_ AxlrVlvNmr03VlvStt : 16|4@1+ (1,0) [0|15] "" Vector__XXX
 SG_ AuxiliaryValve03FailSafeMode : 22|2@1+ (1,0) [0|3] "" Vector__XXX
 SG_ AxlrVlvNmr03EstmtdFlwLmtStts : 29|3@1+ (1,0) [0|7] "" Vector__XXX
 SG_ AuxiliaryValve03ExitReasonCode : 32|6@1+ (1,0) [0|63] "" Vector__XXX
 SG_ AxlrVlv03EstmtdFlwHghRsltn : 48|16@1+ (0.004,-125) [-125|132.02] "%" Vector__XXX

BO_ 2365461758 AV04EF: 8 Vector__XXX
 SG_ AxlrVlvNmr04ExtndPrtEstmtdFlw : 0|8@1+ (1,-125) [-125|125] "%" Vector__XXX
 SG_ AxlrVlvNmr04RtrtPrtEstmtdFlw : 8|8@1+ (1,-125) [-125|125] "%" Vector__XXX
 SG_ AxlrVlvNmr04VlvStt : 16|4@1+ (1,0) [0|15] "" Vector__XXX
 SG_ AuxiliaryValve04FailSafeMode : 22|2@1+ (1,0) [0|3] "" Vector__XXX
 SG_ AxlrVlvNmr04EstmtdFlwLmtStts : 29|3@1+ (1,0) [0|7] "" Vector__XXX
 SG_ AuxiliaryValve04ExitReasonCode : 32|6@1+ (1,0) [0|63] "" Vector__XXX
 SG_ AxlrVlv04EstmtdFlwHghRsltn : 48|16@1+ (0.004,-125) [-125|132.02] "%" Vector__XXX

CM_ BO_ 2364604414 "Secondary or Front Hitch Roll and Pitch";
CM_ SG_ 2364604414 FrontHitchRollAngle "Front hitch roll angle: Measured roll angle of the front three-point hitch expressed in degrees from horizontal alignment with the rear axle of the tractor. Facing the direction of travel, an anti-clockwise rotation would be indicated by a negative n...";
CM_ SG_ 2364604414 FrontHitchRollLimitStatus "Front hitch roll limit status: Parameter used to report the Tractor ECU's present limit status associated with the front hitch roll commands. Value Meaning 000 Not limited 001 Operator limited/controlled (request cannot be implemented) 010 Limited Hi...";
CM_ SG_ 2364604414 FrontHitchRollExitReasonCode "Front hitch roll exit/reason code: This parameter is used to indicate why the front hitch cannot accept remote roll commands or has most recently stopped accepting remote commands.Value Meaning 000000 No reason/all clear 000001 Required level of oper...";
CM_ SG_ 2364604414 FrontHitchPitchAngle "Front hitch pitch angle: Measured pitch angle of the front three-point hitch expressed in degrees from vertical alignment of the upper and lower attachment points. Positive is in the anti-clockwise direction when viewed from the left-hand side of the...";
CM_ SG_ 2364604414 FrontHitchPitchLimitStatus "Front hitch pitch limit status: Parameter used to report the Tractor ECU's present limit status associated with the front hitch pitch commands. Value Meaning 000 Not limited 001 Operator limited/controlled (request cannot be implemented) 010 Limited ...";
CM_ SG_ 2364604414 FrontHitchPitchExitReasonCode "Front hitch pitch exit/reason code: This parameter is used to indicate why the front hitch cannot accept remote pitch commands or has most recently stopped accepting remote commands. Value Meaning 000000 No reason/all clear 000001 Required level of o...";
CM_ BO_ 2364604926 "Primary or Rear Hitch Roll and Pitch";
CM_ SG_ 2364604926 RearHitchRollAngle "Rear hitch roll angle: Measured roll angle of the rear three-point hitch expressed in degrees from horizontal alignment with the rear axle of the tractor. Facing the direction of travel, an anti-clockwise rotation would be indicated by a negative num...";
CM_ SG_ 2364604926 RearHitchRollLimitStatus "Rear hitch roll limit status: Parameter used to report the Tractor ECU's present limit status associated with the rear hitch roll commands. Value Meaning 000 Not limited 001 Operator limited/controlled (request cannot be implemented) 010 Limited High...";
CM_ SG_ 2364604926 RearHitchRollExitReasonCode "Rear hitch roll exit/reason code: This parameter is used to indicate why the rear hitch cannot accept remote roll commands or has most recently stopped accepting remote commands. Value Meaning 000000 No reason/all clear 000001 Required level of opera...";
CM_ SG_ 2364604926 RearHitchPitchAngle "Rear hitch pitch angle: Measured pitch angle of the rear three-point hitch expressed in degrees from vertical alignment of the upper and lower attachment points. Positive is in the anti-clockwise direction when viewed from the left-hand side of the t...";
CM_ SG_ 2364604926 RearHitchPitchLimitStatus "Rear hitch pitch limit status: Parameter used to report the Tractor ECU's present limit status associated with the rear hitch pitch commands. Value Meaning 000 Not limited 001 Operator limited/controlled (request cannot be implemented) 010 Limited Hi...";
CM_ SG_ 2364604926 RearHitchPitchExitReasonCode "Rear hitch pitch exit/reason code: This parameter is used to indicate why the rear hitch cannot accept remote pitch commands or has most recently stopped accepting remote commands. Value Meaning 000000 No reason/all clear 000001 Required level of ope...";
CM_ BO_ 2364605182 "Primary or Rear Hitch Roll and Pitch command";
CM_ SG_ 2364605182 RrHthPthSnstvtCmmnd "Rear hitch pitch sensitivity command: Command for setting the sensitivity of the rear hitch pitch control expressed as a percentage of the maximum gain. 0 % indicates minimal gain in the control loop; 100 %, the maximum gain. Values near 0 may result...";
CM_ SG_ 2364605182 RearHitchRollCommand "Rear hitch roll command: Command for setting the roll angle of the rear three-point hitch expressed in degrees with 0 being horizontally aligned with the rear axle of the tractor. Facing the direction of travel, an anti-clockwise rotation would be in...";
CM_ SG_ 2364605182 RearHitchRollSensitivityCommand "Rear hitch roll sensitivity command: Command for setting the sensitivity of the rear hitch roll control expressed as a percentage of the maximum gain. 0 % indicates minimal gain in the control loop; 100 %, the maximum gain. Values near 0 may result i...";
CM_ SG_ 2364605182 RearHitchPitchCommand "Rear hitch pitch command: Command for setting the pitch angle of the rear three-point hitch expressed in degrees from vertical alignment of the upper and lower attachment points. Positive is in the anti-clockwise direction when viewed from the left-h...";
CM_ BO_ 2365473278 "Lighting command";
CM_ SG_ 2365473278 ImplementOemOption1LightCommand "Implement OEM option 1 light — Command: Command for activating or deactivating an implement's OEM (original equipment manufacturer) option 1 light, which is provided to meet special needs on implements, such as tank inspection or filling lights. Valu...";
CM_ SG_ 2365473278 ImplementOemOption2LightCommand "Implement OEM option 2 light — Command: Command for activating or deactivating an implement's OEM option 2 light, which is provided to meet special needs on implements, such as tank inspection or filling lights. Value Meaning 00 Deactivate 01 Activat...";
CM_ SG_ 2365473278 RotatingBeaconLightCommand "Rotating beacon light — Command: Command for activating or deactivating slow-moving vehicle indicator lights on the tractor or implement or both. Activation of the slow-moving vehicle lights implies that the controller should manipulate the lighting ...";
CM_ SG_ 2365473278 TractorFrontFogLightsCommand "Tractor front fog lights — Command: Command for activating or deactivating the tractor's front fog lights. Value Meaning 00 Deactivate 01 Activate 10 Reserved 11 Don't care";
CM_ SG_ 2365473278 TrtrFrntHghMntdWrkLghtsCmmnd "Tractor front high-mounted work lights — Command: Command for activating or deactivating the tractor's front high-mounted work lights. Value Meaning 00 Deactivate 01 Activate 10 Reserved 11 Don't care";
CM_ SG_ 2365473278 TrtrFrntLwMntdWrkLghtsCmmnd "Tractor front low-mounted work lights — Command: Command for activating or deactivating the tractor's front low-mounted work lights. Value Meaning 00 Deactivate 01 Activate 10 Reserved 11 Don't care";
CM_ SG_ 2365473278 TrtrUndrsdMntdWrkLghtsCmmnd "Tractor underside-mounted work lights — Command: Command for activating or deactivating the tractor's underside-mounted work lights. Value Meaning 00 Deactivate 01 Activate 10 Reserved 11 Don't care";
CM_ SG_ 2365473278 DaytimeRunningLightsCommand "Daytime running lights — Command: Command for activating or deactivating the tractor's or powered vehicle's running lights. Value Meaning 00 Deactivate 01 Activate 10 Reserved 11 Don't care";
CM_ SG_ 2365473278 AlternateHeadlightsCommand "Alternate headlights — Command: Command for activating or deactivating the machine's alternate headlights (on which only low-beam is available). The alternate position lamps are intended for use with loader and snow ploughs where the primary headligh...";
CM_ SG_ 2365473278 LowBeamHeadlightsCommand "Low-beam headlights — Command: Command to activate or deactivate the machine's low-beam headlights 5). Value Meaning 00 Deactivate 01 Activate 10 Reserved 11 Don't care";
CM_ SG_ 2365473278 HighBeamHeadlightsCommand "High-beam headlights — Command: Command for activating or deactivating the machine's high-beam headlights4). Value Meaning 00 Deactivate 01 Activate 10 Reserved 11 Don't care";
CM_ SG_ 2365473278 RightTurnSignalLightsCommand "Right-turn signal lights — Command: Command for activating or deactivating right-turn signal lights on the tractor and all connected implements. Value Meaning 00 Deactivate 01 Activate 10 Reserved 11 Don't care";
CM_ SG_ 2365473278 LeftTurnSignalLightsCommand "Left-turn signal lights — Command: Command for activating or deactivating left-turn signal lights on the tractor and all connected implements. Value Meaning 00 Deactivate 01 Activate 10 Reserved 11 Don't care";
CM_ SG_ 2365473278 BackUpLightsAndAlarmHornCommand "Back-up lights and alarm horn — Command: Command for activating or deactivating the back-up lights and/or associated alarm if required. Value Meaning 00 Deactivate 01 Activate 10 Reserved 11 Don't care";
CM_ SG_ 2365473278 CentreStopLightsCommand "Centre stop lights — Command: Command for activating or deactivating the tractor's and implement's centre stop lights. Value Meaning 00 Deactivate 01 Activate 10 Reserved 11 Don't care";
CM_ SG_ 2365473278 RightStopLightsCommand "Right stop lights — Command: Command for activating or deactivating the tractor's and implement's right stop lights. Value Meaning 00 Deactivate 01 Activate 10 Reserved 11 Don't care";
CM_ SG_ 2365473278 LeftStopLightsCommand "Left stop lights — Command: Command for activating or deactivating the tractor's and implement's left stop lights. Value Meaning 00 Deactivate 01 Activate 10 Reserved 11 Don't care";
CM_ SG_ 2365473278 ImplementClearanceLightsCommand "Implement clearance lights — Command: Command for activating or deactivating the implement's high-mounted clearance lights. Value Meaning 00 Deactivate 01 Activate 10 Reserved 11 Don't care";
CM_ SG_ 2365473278 TractorClearanceLightsCommand "Tractor clearance lights — Command: Command for activating or deactivating the tractor's high-mounted clearance and centre ID lights. Value Meaning 00 Deactivate 01 Activate 10 Reserved 11 Don't care";
CM_ SG_ 2365473278 ImplmntMrkrPstnLghtsCmmnd "Implement marker (position) lights — Command: Command for activating or deactivating the implement's, front position lights, rear red tail lights, side amber running lights, license-plate (number-plate) lights, and instrument and switch back lights. ...";
CM_ SG_ 2365473278 TrtrMrkrPstnLghtsCmmnd "Tractor marker (position) lights — Command: Command for activating or deactivating the tractor's front position lights, rear red tail lights, side amber running lights, license-plate (number-plate) lights, and instrument and switch back lights. Value...";
CM_ SG_ 2365473278 RearFogLightsCommand "Rear fog lights — Command: Command for activating or deactivating the tractor's or implement's rear fog lights, or both. Value Meaning 00 Deactivate 01 Activate 10 Reserved 11 Don't care";
CM_ SG_ 2365473278 TrtrRrLwMntdWrkLghtsCmmnd "Tractor rear low-mounted work lights — Command: Command for activating or deactivating the tractor's rear low-mounted work lights. Value Meaning 00 Deactivate 01 Activate 10 Reserved 11 Don't care";
CM_ SG_ 2365473278 TrtrRrHghMntdWrkLghtsCmmnd "Tractor rear high-mounted work lights — Command: Command for activating or deactivating the tractor's rear high-mounted work lights. Value Meaning 00 Deactivate 01 Activate 10 Reserved 11 Don't care";
CM_ SG_ 2365473278 TrtrSdLwMntdWrkLghtsCmmnd "Tractor side low-mounted work lights — Command: Command for activating or deactivating the tractor's side low-mounted work lights. Value Meaning 00 Deactivate 01 Activate 10 Reserved 11 Don't care";
CM_ SG_ 2365473278 TrtrSdHghMntdWrkLghtsCmmnd "Tractor side high-mounted work lights — Command: Command for activating or deactivating the tractor's side high-mounted work lights. Value Meaning 00 Deactivate 01 Activate 10 Reserved 11 Don't care";
CM_ SG_ 2365473278 ImplmntRghtFrwrdWrkLghtsCmmnd "Implement right forward work lights — Command: Command for activating or deactivating the forward-facing work lights towards the right end of the implement. Value Meaning 00 Deactivate 01 Activate 10 Reserved 11 Don't care";
CM_ SG_ 2365473278 ImplmntLftFrwrdWrkLghtsCmmnd "Implement left forward work lights — Command: Command for activating or deactivating the forward-facing work lights towards the left end of the implement. Value Meaning 00 Deactivate 01 Activate 10 Reserved 11 Don't care";
CM_ SG_ 2365473278 LghtngDtMssgRqstCmmnd "Lighting data message request — Command: Command for requesting the lighting data message from all lighting controllers, providing the state of all lights. Value Meaning 00 No data requested 01 Data requested 10 Reserved 11 Don't care";
CM_ SG_ 2365473278 ImplmntRghtFngWrkLghtsCmmnd "Implement right-facing work lights — Command: Command for activating or deactivating work lights mounted on an implement for illuminating beyond the right end of the implement.Value Meaning 00 Deactivate 01 Activate 10 Reserved 11 Don't care";
CM_ SG_ 2365473278 ImplmntLftFngWrkLghtsCmmnd "Implement left-facing work lights — Command: Command for activating or deactivating work lights mounted on an implement for illuminating beyond the left end of the implement. Value Meaning 00 Deactivate 01 Activate 10 Reserved 11 Don't care";
CM_ SG_ 2365473278 ImplementRearWorkLightsCommand "Implement rear work lights — Command: Command for activating or deactivating the implement's rear work lights. Value Meaning 00 Deactivate 01 Activate 10 Reserved 11 Don't care";
CM_ BO_ 2550660862 "General Purpose Valve Pressure";
CM_ SG_ 2550660862 GnrlPrpsVlvLdSnsPrssr "General-purpose valve load sense pressure: The maximum of the currently measured pressures of a general-purpose valve's work port A and work port B.";
CM_ SG_ 2550660862 GnrlPrpsVlvPltPrssr "General-purpose valve pilot pressure: The measured pressure of a general-purpose valve's pilot supply port.";
CM_ SG_ 2550660862 GnrlPrpsVlvAssmlLdSnsPrssr "General-purpose valve assembly load sense pressure: The maximum measured pressure of a general-purpose valve assembly's current collective load sense pressures where a valve assembly can consist of two or more valves.";
CM_ SG_ 2550660862 GnrlPrpsVlvAssmlSpplPrssr "General-purpose valve assembly supply pressure: The measured pressure of the hydraulic supply port to a valve assembly. ";
CM_ BO_ 2566655742 "Primary or Rear Hitch Roll and Pitch Sensitivity";
CM_ SG_ 2566655742 RearHitchPitchSensitivity "Rear hitch pitch sensitivity: The current sensitivity of the rear hitch pitch control expressed as a percentage of the maximum gain. 0 % indicates minimal gain in the control loop; 100 %, the maximum gain. Values near 0 may result in no reaction by t...";
CM_ SG_ 2566655742 RearHitchRollSensitivity "Rear hitch roll sensitivity: The current sensitivity of the rear hitch roll control expressed as a percentage of the maximum gain. 0 % indicates minimal gain in the control loop; 100 %, the maximum gain. Values near 0 may result in no reaction by the...";
CM_ BO_ 2566655998 "Secondary or Front Hitch Roll and Pitch Sensitivity";
CM_ SG_ 2566655998 FrontHitchRollSensitivity "Front hitch roll sensitivity: The current sensitivity of the front hitch roll control expressed as a percentage of the maximum gain. 0 % indicates minimal gain in the control loop; 100 %, the maximum gain. Values near 0 may result in no reaction by t...";
CM_ SG_ 2566655998 FrontHitchPitchSensitivity "Front hitch pitch sensitivity: The current sensitivity of the front hitch pitch control expressed as a percentage of the maximum gain. 0 % indicates minimal gain in the control loop; 100 %, the maximum gain. Values near 0 may result in no reaction by...";
CM_ BO_ 2566768126 "ECU Identification Information";
CM_ SG_ 2566768126 EcuManufacturerName "ECU Manufacturer Name: The name of the manufacturer of the physical ECU._x000D__x000D_This name may be different than the manufacturer identified by the Manufacturer Code (SPN 2838) and listed in table B10 of J1939.";
CM_ SG_ 2566768126 EcuPartNumber "ECU Part Number: The part number of the physical ECU.";
CM_ SG_ 2566768126 EcuSerialNumber "ECU Serial Number: The serial number of the physical ECU.";
CM_ SG_ 2566768126 EcuLocation "ECU Location: The location of the ECU within a network.";
CM_ SG_ 2566768126 EcuType "ECU Type: The type of ECU.  One example of a use of the ECU type could be for classifying ECU capabilities, such as I/O.";
CM_ SG_ 2566768126 EcuHardwareId "ECU Hardware ID: The ECU Hardware ID provides information to identify a specific ECU hardware version._x000D__x000D_As an example, on a CAN network, this parameter can be used to uniquely identify the hardware version that is relevant for the interfa...";
CM_ BO_ 2566799614 "Lighting Data";
CM_ SG_ 2566799614 ImplementOemOption1Light "Implement OEM option 1 light: Parameter providing measured data from the implement's OEM option 1 light. Value Meaning 00 Deactivated 01 Activated 10 Fault detected 11 Not available";
CM_ SG_ 2566799614 ImplementOemOption2Light "Implement OEM option 2 light: Parameter providing measured data from the implement's OEM option 2 light. Value Meaning 00 Deactivated 01 Activated 10 Fault detected 11 Not available";
CM_ SG_ 2566799614 LeftTurnSignalLights "Left-turn signal lights: Parameter providing measured data from the tractor's and attached implement's left-turn signal lights. Value Meaning 00 Deactivated 01 Activated 10 Fault detected 11 Not available";
CM_ SG_ 2566799614 RearFogLights "Rear fog lights: Parameter providing measured data from the tractor's or implement's rear fog lights, or both. Value Meaning 00 Deactivated 01 Activated 10 Fault detected 11 Not available";
CM_ SG_ 2566799614 RightTurnSignalLights "Right-turn signal lights: Parameter providing measured data from the tractor's and attached implement's right-turn signal lights. Value Meaning 00 Deactivated 01 Activated 10 Fault detected 11 Not available";
CM_ SG_ 2566799614 RotatingBeaconLight "Rotating beacon light: Parameter providing measured data from the beacon light on the tractor or attached implement.Value Meaning 00 Deactivated 01 Activated 10 Fault detected 11 Not available";
CM_ SG_ 2566799614 TractorFrontFogLights "Tractor front fog lights: Parameter providing measured data from the tractor's front fog lights. Value Meaning 00 Deactivated 01 Activated 10 Fault detected 11 Not available";
CM_ SG_ 2566799614 TractorRearLowMountedWorkLights "Tractor rear low-mounted work lights: Parameter providing measured data from the tractor's rear low-mounted work lights. Value Meaning 00 Deactivated 01 Activated 10 Fault detected 11 Not available";
CM_ SG_ 2566799614 TractorSideLowMountedWorkLights "Tractor side low-mounted work lights: Parameter providing measured data from the tractor's side low-mounted work lights. Value Meaning 00 Deactivated 01 Activated 10 Fault detected 11 Not available";
CM_ SG_ 2566799614 TrtrFrntHghMntdWrkLghts "Tractor front high-mounted work lights: Parameter providing measured data from the tractor's front high-mounted work lights. Value Meaning 00 Deactivated 01 Activated 10 Fault detected 11 Not available";
CM_ SG_ 2566799614 TrtrFrntLwMntdWrkLghts "Tractor front low-mounted work lights: Parameter providing measured data from the tractor's front low-mounted work lights. Value Meaning 00 Deactivated 01 Activated 10 Fault detected 11 Not available";
CM_ SG_ 2566799614 TrtrRrHghMntdWrkLghts "Tractor rear high-mounted work lights: Parameter providing measured data from the tractor's rear high-mounted work lights. Value Meaning 00 Deactivated 01 Activated 10 Fault detected 11 Not available";
CM_ SG_ 2566799614 TrtrSdHghMntdWrkLghts "Tractor side high-mounted work lights: Parameter providing measured data from the tractor's side high-mounted work lights. Value Meaning 00 Deactivated 01 Activated 10 Fault detected 11 Not available";
CM_ SG_ 2566799614 TrtrUndrsdMntdWrkLghts "Tractor underside-mounted work lights: Parameter providing measured data from the tractor's underside-mounted work lights. Value Meaning 00 Deactivated 01 Activated 10 Fault detected 11 Not available";
CM_ SG_ 2566799614 DaytimeRunningLights "Daytime running lights: Parameter providing measured data from the tractor's or powered vehicle's running lights. Value Meaning 00 Deactivated 01 Activated 10 Fault detected 11 Not available";
CM_ SG_ 2566799614 AlternateHeadlights "Alternate headlights: Parameter providing measured data from the alternate headlights.Value Meaning 00 Deactivated 01 Activated 10 Fault detected 11 Not available";
CM_ SG_ 2566799614 LowBeamHeadlights "Low-beam headlights: Parameter providing measured data from the machine's low-beam headlights 4). Value Meaning 00 Deactivated 01 Activated 10 Fault detected 11 Not available";
CM_ SG_ 2566799614 HighBeamHeadlights "High-beam headlights: Parameter providing measured data from the machine's high-beam headlights Value Meaning 00 Deactivated 01 Activated 10 Fault detected 11 Not available";
CM_ SG_ 2566799614 BackUpLightsAndAlarmHorn "Back-up lights and alarm horn: Parameter providing measured data from the back-up lights, associated alarm or both. Value Meaning 00 Deactivated 01 Activated 10 Fault detected 11 Not available";
CM_ SG_ 2566799614 CenterStopLights "Center stop lights: Parameter providing measured data from the tractor's and attached implement's centre stop lights. Value Meaning 00 Deactivated 01 Activated 10 Fault detected 11 Not available";
CM_ SG_ 2566799614 RightStopLights "Right stop lights: Parameter providing measured data from the tractor's and attached implement's right stop lights. Value Meaning 00 Deactivated 01 Activated 10 Fault detected 11 Not available";
CM_ SG_ 2566799614 LeftStopLights "Left stop lights: Parameter providing measured data from the tractor's and attached implement's left stop lights. Value Meaning 00 Deactivated 01 Activated 10 Fault detected 11 Not available";
CM_ SG_ 2566799614 ImplementClearanceLights "Implement clearance lights: Parameter providing measured data from an attached implement's high-mounted clearance lights. Value Meaning 00 Deactivated 01 Activated 10 Fault detected 11 Not available";
CM_ SG_ 2566799614 TractorClearanceLights "Tractor clearance lights: Parameter providing measured data from the tractor's high-mounted clearance and centre ID lights. Value Meaning 00 Deactivated 01 Activated 10 Fault detected 11 Not available";
CM_ SG_ 2566799614 ImplementMarkerPositionLights "Implement marker (position) lights: Parameter providing measured data from an attached implement, marker lights, including front position lights, rear tail lights, side running lights, license-plate (number-plate) lights, and instrument and switch ba...";
CM_ SG_ 2566799614 TractorMarkerPositionLights "Tractor marker (position) lights: Parameter providing measured data from the tractor's marker lights, including front-position lights, rear tail lights, side running lights, license-plate (number-plate) lights, and instrument and switch back lights. ...";
CM_ SG_ 2566799614 ImplementRightForwardWorkLights "Implement right forward work lights: Parameter providing measured data from the forward-facing work lights towards the right end of the implement. Value Meaning 00 Deactivated 01 Activated 10 Fault detected 11 Not available";
CM_ SG_ 2566799614 ImplementLeftForwardWorkLights "Implement left forward work lights: Parameter providing measured data from the forward-facing work lights towards the left end of the implement. Value Meaning 00 Deactivated 01 Activated 10 Fault detected 11 Not available";
CM_ SG_ 2566799614 ImplementRightFacingWorkLights "Implement right-facing work lights: Parameter providing measured data from the work lights mounted on an implement for illuminating beyond the right end of the implement. Value Meaning 00 Deactivated 01 Activated 10 Fault detected 11 Not available...";
CM_ SG_ 2566799614 ImplementLeftFacingWorkLights "Implement left-facing work lights: Parameter providing measured data from the work lights mounted on an implement for illuminating beyond the left end of the implement. Value Meaning 00 Deactivated 01 Activated 10 Fault detected 11 Not available...";
CM_ SG_ 2566799614 ImplementRearWorkLights "Implement rear work lights: Parameter providing measured data from the implement's rear work lights. Value Meaning 00 Deactivated 01 Activated 10 Fault detected 11 Not available";
CM_ BO_ 2566839038 "Software Identification";
CM_ SG_ 2566839038 NmrOfSftwrIdntftnFlds "Number of Software Identification Fields: Number of software identification designators represented in the software identification parameter group.";
CM_ SG_ 2566839038 SoftwareIdentification "Software Identification: Software identification of an electronic module.  As an example, this parameter may be represented with ASCII characters MMDDYYaa where MM is the month, DD is the day, YY is the year, and aa is the revision number._x000D__x00...";
CM_ BO_ 2566842110 "Time/Date";
CM_ SG_ 2566842110 Day "Day: These three parameters provide the current date at the Universal Time Coordinate (UTC). If the local hour offset parameter (A.4) is equal to 125 (0xFA), then the date parameter is the local date instead of UTC date.";
CM_ SG_ 2566842110 Hours "Hours: These three parameters provide the current time at the Universal Time Coordinate (UTC). If the local hour offset parameter (A.4) is equal to 125 (0xFA), then the time parameter is the local time instead of UTC.";
CM_ SG_ 2566842110 LocalHourOffset "Local hour offset: Local hour offset is the number of hours between the Universal Time Coordinate (UTC) time and date and a local time and date. This value is added to UTC time and date to determine the local time and date. The local offset is a posi...";
CM_ SG_ 2566842110 LocalMinuteOffset "Local minute offset: Local minute offset is the number of minutes between the Universal Time Coordinate (UTC) time and date and a local time and date. This value is added to UTC time and date to determine the local time and date. The local offset is ...";
CM_ SG_ 2566842110 Minutes "Minutes: These three parameters provide the current time at the Universal Time Coordinate (UTC). If the local hour offset parameter (A.4) is equal to 125 (0xFA), then the time parameter is the local time instead of UTC.";
CM_ SG_ 2566842110 Month "Month: These three parameters provide the current date at the Universal Time Coordinate (UTC). If the local hour offset parameter (A.4) is equal to 125 (0xFA), then the date parameter is the local date instead of UTC date.";
CM_ SG_ 2566842110 Seconds "Seconds: These three parameters provide the current time at the Universal Time Coordinate (UTC). If the local hour offset parameter (A.4) is equal to 125 (0xFA), then the time parameter is the local time instead of UTC.";
CM_ SG_ 2566842110 Year "Year: These three parameters provide the current date at the Universal Time Coordinate (UTC). If the local hour offset parameter (A.4) is equal to 125 (0xFA), then the date parameter is the local date instead of UTC date.";
CM_ BO_ 2364604670 "Secondary or Front Hitch Roll and Pitch command";
CM_ SG_ 2364604670 FrontHitchRollCommand "Front hitch roll command: Command for setting the roll angle of the front three-point hitch expressed in degrees with 0 being horizontally aligned with the rear axle of the tractor. Facing the direction of travel, an anti-clockwise rotation would be ...";
CM_ SG_ 2364604670 FrntHthRllSnstvtCmmnd "Front hitch roll sensitivity command: Command for setting the sensitivity of the front hitch roll control expressed as a percentage of the maximum gain. 0 % indicates minimal gain in the control loop; 100 %, the maximum gain. Values near 0 may result...";
CM_ SG_ 2364604670 FrontHitchPitchCommand "Front hitch pitch command: Command for setting the pitch angle of the front three-point hitch expressed in degrees from vertical alignment of the upper and lower attachment points. Positive is in the anti-clockwise direction when viewed from the left...";
CM_ SG_ 2364604670 FrntHthPthSnstvtCmmnd "Front hitch pitch sensitivity command: Command for setting the sensitivity of the front hitch pitch control expressed as a percentage of the maximum gain. 0 % indicates minimal gain in the control loop; 100 %, the maximum gain. Values near 0 may resu...";
CM_ BO_ 2360147710 "Agricultural Guidance Machine Info";
CM_ SG_ 2360147710 EstimatedCurvature "Estimated curvature: Machine steering system's estimate of the curvature of the current turn. Curvature is positive when the vehicle is moving forward and turning to the driver's right.";
CM_ SG_ 2360147710 MechanicalSystemLockout "Mechanical system lockout: State of a lockout switch that allows operators to disable automatic steering system functions. Value Meaning 00 Not active 01 Active 10 Error indication 11 Not available";
CM_ SG_ 2360147710 GuidanceSteeringSystemReadiness "Guidance steering system readiness: Machine steering system indicates that it is free from faults that would preclude guidance system";
CM_ SG_ 2360147710 SteeringInputPositionStatus "Steering input position status: operation.";
CM_ SG_ 2360147710 RequestResetCommandStatus "Request reset command status: Machine steering system request to the automatic guidance system to change Curvature Command Status state from “Intended to steer” to “Not intended to steer”. Value Meaning 00 Reset not required 01 Reset required 10 Erro...";
CM_ SG_ 2360147710 GuidanceLimitStatus "Guidance Limit Status: This parameter is used to report the steering system’s present limit status associated with guidance commands that are persistent (i.e. not transient/temporary/one-shot). Value Meaning 000 Not limited 001 Operator limited/contr...";
CM_ SG_ 2360147710 GdnSstmCmmndExtRsnCd "Guidance system command exit/reason code: This parameter is used to indicate why the guidance system cannot currently accept remote commands or has most recently stopped accepting remote commands. Value Meaning 000000 No reason/all clear 000001 Requi...";
CM_ SG_ 2360147710 GdnSstmRmtEnggSwthStts "Guidance system Remote Engage Switch Status: ";
CM_ BO_ 2360213246 "Agricultural Guidance System command";
CM_ SG_ 2360213246 CurvatureCommand "Curvature command: Desired course curvature over ground that a machine's steering system is required to achieve. The desired path is determined by the automatic guidance system expressed as the inverse of the instantaneous radius of curvature of the ...";
CM_ SG_ 2360213246 CurvatureCommandStatus "Curvature command status: This parameter indicates whether the guidance system is attempting to control steering with this command. Value Meaning 00 Not intended to steer 01 Intended to steer 10 Reserved 11 Not available";
CM_ BO_ 2361720574 "General Purpose Valve command";
CM_ SG_ 2361720574 GnrlPrpsVlvPrtFlwCmmnd "General-purpose valve port flow - Command: Command for setting the flow through the extend or retract port of a general-purpose valve, expressed as a percentage of full flow. Zero percent indicates no flow, 100 % indicates maximum flow; the flow retu...";
CM_ SG_ 2361720574 GeneralPurposeValveStateCommand "General-purpose valve state - Command: Command for setting a general-purpose valve state. With float enabled, hydraulic fluid may flow to or from the valve as driven by the implement. Data length: 4 bitsValue Meaning 0000 Block 0001 Extend 0010 Retra...";
CM_ SG_ 2361720574 GnrlPrpsVlFlSfMdCmmnd "General-purpose value fail safe mode - Command: Command for setting the fail safe mode of a general-purpose valve. Data length: 2 bitsValue Meaning 00 Block 01 Float 10 Reserved 11 Don't care";
CM_ SG_ 2361720574 GPpsVvPtFwExtddRstCd "General-purpose valve port flow - Extended Resolution Command: Command for setting the flow through the extend or retract port of a general-purpose valve, expressed as a percentage of full flow. 0 % indicates no flow, 100 % indicates maximum flow; th...";
CM_ BO_ 2361786110 "General Purpose Valve measured flow";
CM_ SG_ 2361786110 GnrlPrpsVlvExtndPrtMsrdFlw "General-purpose valve extend port measured flow: Measured flow through the extend port of a general-purpose valve, expressed as a percentage of full flow. Zero percent indicates no flow, 100 % indicates maximum flow, −100 % indicates maximum flow ret...";
CM_ SG_ 2361786110 GnrlPrpsVlvRtrtPrtMsrdFlw "General-purpose valve retract port measured flow: Measured flow through the retract port of a general-purpose valve, expressed as a percentage of full flow. Zero percent indicates no flow, 100 % indicates maximum flow, −100 % indicates maximum flow r...";
CM_ SG_ 2361786110 GnrlPrpsVlvExtndPrtPrssr "General-purpose valve extend port pressure: The measured nominal pressure at the extend port of a general-purpose valve. ";
CM_ SG_ 2361786110 GnrlPrpsVlvRtrtPrtPrssr "General-purpose valve retract port pressure: The measured nominal pressure at the retract port of a general-purpose valve. ";
CM_ SG_ 2361786110 GnrlPrpsVlvRtrnPrtPrssr "General-purpose valve return port pressure: The measured nominal pressure at the return port of a general-purpose valve. ";
CM_ SG_ 2361786110 GnrlPrpsVlvMsrdLmtStts "General-purpose valve measured limit status: This parameter is used to report the Tractor ECU's present measured flow limit status associated with general-purpose valve flow commands that are persistent. Data length: 3 bits Value Meaning 000 Not limi...";
CM_ BO_ 2361851646 "General Purpose Valve estimated flow";
CM_ SG_ 2361851646 GnrlPrpsVlvExtndPrtEstmtdFlw "General-purpose valve extend port estimated flow: The value reported by the controller of flow through the extend port of a general-purpose valve, which could be based on the commanded position of the valve. Zero percent indicates no flow, 100 % indi...";
CM_ SG_ 2361851646 GnrlPrpsVlvRtrtPrtEstmtdFlw "General-purpose valve retract port estimated flow: The value reported by the controller of flow through the retract port of a general-purpose valve, which could be based on the commanded position of the valve. Zero percent indicates no flow, 100 % in...";
CM_ SG_ 2361851646 GeneralPurposeValveState "General-purpose valve state: The measured state of a general-purpose valve. A blocked state means that the valve is closed and there is no flow from or to the valve and the that fluid may be under pressure. A floating state means that there is no con...";
CM_ SG_ 2361851646 GeneralPurposeValveFailSafeMode "General-purpose valve fail safe mode: The measured state of the fail safe mode of a general-purpose valve. Data length: 2 bits Value Meaning 00 Block 01 Float 10 Error indication 11 Not available";
CM_ SG_ 2361851646 GnrlPrpsVlvEstmtdLmtStts "General-purpose valve estimated limit status: This parameter is used to report the Tractor ECU's present estimated flow limit status associated with general-purpose valve flow commands that are persistent. Data length: 3 bits Value Meaning 000 Not li...";
CM_ SG_ 2361851646 GnrlPrpsVlvExtRsnCd "General-purpose valve exit/reason code: This parameter is used to indicate why the general purpose valve cannot accept remote commands or has most recently stopped accepting remote commands. Data length: 5 bits Value Meaning 00000 No reason/all clear...";
CM_ SG_ 2361851646 GPpsVvExtdPtHRstEsttdFw "General-purpose valve extend port high resolution estimated flow: The value reported by the controller of flow through the extend port of a general-purpose valve, which could be based on the commanded position of the valve. If this parameter is “not ...";
CM_ SG_ 2361851646 GPpsVvRttPtHRstEsttdFw "General-purpose valve retract port high resolution estimated flow: The value reported by the controller of flow through the retract port of a general-purpose valve, which could be based on the commanded position of the valve. If this parameter is “no...";
CM_ BO_ 2563571454 "Request for Repetition Rate";
CM_ SG_ 2563571454 PgnOfTheRequest1 "PGN of the request #1: PGN, that the repetition rate is requested for";
CM_ SG_ 2563571454 RepetitionRateCommand "Repetition rate — Command: Parameter defining the commanded repetition rate of the transmission of the message with the associated PGN. The value of 0 implies that the default rate is desired, while a value of 65 535 implies no change is requested.";
CM_ BO_ 2362507006 "Background lighting level command";
CM_ SG_ 2362507006 BkgrndIllmntnLvlCmmnd "Background illumination level — Command: Command for setting the instrument and control illumination level.";
CM_ BO_ 2364547838 "Machine Selected Speed";
CM_ SG_ 2364547838 MachineSelectedDirection "Machine selected direction: Indicates the current direction of travel of the machine. Value    Meaning 00         Reverse 01         Forward 10         Error indication 11         Not available";
CM_ SG_ 2364547838 MachineSelectedSpeedSource "Machine selected speed source: An indication of the speed source that is currently being reported in the machine selected speed parameter (SPN-4305). Simulated speed is a system-generated speed message to permit implement operations when the machine ...";
CM_ SG_ 2364547838 MachineSelectedSpeedLimitStatus "Machine selected speed limit status: This parameter is used to report the Tractor ECU's present limit status associated with a parameter whose commands are persistent (i.e. not transient/temporary/one-shot). Value Meaning 000    Not limited 001    Op...";
CM_ SG_ 2364547838 MhnSltdSpdExtRsnCd "Machine selected speed exit/reason code: This parameter is used to indicate why the vehicle speed control unit cannot currently accept remote commands or has most recently stopped accepting remote commands. Value      Meaning 000000   No reason/all c...";
CM_ SG_ 2364547838 MachineSelectedSpeed "Machine selected speed: Current value of the speed as determined from a number of sources by the machine. This parameter reports the value of one of the currently available machine speeds (wheel-, ground-, or navigational-based), which the machine ha...";
CM_ SG_ 2364547838 MachineSelectedDistance "Machine selected distance: Actual distance travelled by the machine based on the value of selected machine speed (SPN 4305). When the distance exceeds 4 211 081,215 m, the value shall be reset to zero and incremented as additional distance accrues.";
CM_ BO_ 2364597502 "Heartbeat Message";
CM_ SG_ 2364597502 HeartbeatSequenceNumber "Heartbeat sequence number: This parameter indicates the sequence number of the heartbeat message. The heartbeat message is used to determine the integrity of the communication of messages and parameters transmitted by a CF. Value Meaning 0 - 250 Vali...";
CM_ BO_ 2364620542 "Secondary or Front Hitch Yaw command";
CM_ SG_ 2364620542 FrontHitchYawCommand "Front hitch yaw command: Command for setting the yaw angle of the front three-point hitch like defined in A.19.27 and A.19.28. To enable the command, Front hitch yaw angle actual control mode (see A.19.29) must be value 0101.";
CM_ BO_ 2364620798 "Primary or Rear Hitch Yaw command";
CM_ SG_ 2364620798 RearHitchYawCommand "Rear hitch yaw command: Command for setting the yaw angle of the rear three-point hitch like defined in A.19.45 and A.19.46. To enable the command, Rear hitch yaw angle actual control mode (see A.19.47) must be value 0101.";
CM_ BO_ 2365293310 "Primary or Rear Hitch Yaw";
CM_ SG_ 2365293310 RearHitchYawAngle "Rear hitch yaw angle: Measured yaw angle of rear hitch relative to the reference frame indicated by A.19.46 parameter. The yaw angle measurement around the yaw (z-axis) of the hitch. The yaw angle is defined to be the angle from the null position on ...";
CM_ SG_ 2365293310 RearHitchYawAngleReferenceFrame "Rear hitch yaw angle reference frame: This parameter is used to indicate the reference frame for the yaw angle of the rear hitch. Value Meaning 0000 Main body of the machine 0001 Body of the hitch 0010 Direction of travel 0011 to 1101 Reserved 1110 N...";
CM_ SG_ 2365293310 RrHthYwAnglAtlCntrlMd "Rear hitch yaw angle actual control mode: This parameter is used to indicate the control mode active in the tractor. Value Meaning 0000 Disabled, yaw angle is locked in a position (e.g. transport). 0001 Direct hydraulic valve control, manual operatio...";
CM_ SG_ 2365293310 RearHitchYawLimitStatus "Rear hitch yaw limit status: Parameter used to report the Tractor ECU's present limit status associated with the rear hitch yaw commands. Value Meaning 000 Not limited 001 Operator limited/controlled (request cannot be implemented) 010 Limited High (...";
CM_ SG_ 2365293310 RearHitchYawExitReasonCode "Rear hitch yaw exit/reason code: This parameter is used to indicate why the rear hitch cannot accept remote yaw commands or has most recently stopped accepting remote commands. Value Meaning 000000 No reason/all clear 000001 Required level of operato...";
CM_ BO_ 2365293566 "Secondary or Front Hitch Yaw";
CM_ SG_ 2365293566 FrontHitchYawAngle "Front hitch yaw angle: Measured yaw angle of front hitch relative to the reference frame indicated by A.19.28 parameter. The yaw angle measurement around the yaw (z-axis) of the hitch. The yaw angle is defined to be the angle from the null position o...";
CM_ SG_ 2365293566 FrntHthYwAnglRfrnFrm "Front hitch yaw angle reference frame: This parameter is used to indicate the reference frame for the yaw angle of the front hitch.Value Meaning 0000 Main body of the machine 0001 Body of the hitch 0010 Direction of travel 0011 to 1101 Reserved 1110 ...";
CM_ SG_ 2365293566 FrntHthYwAnglAtlCntrlMd "Front hitch yaw angle actual control mode: This parameter is used to indicate the control mode active in the tractor.Value Meaning 0000 Disabled, yaw angle is locked in a position (e.g. transport). 0001 Direct hydraulic valve control, manual operatio...";
CM_ SG_ 2365293566 FrontHitchYawLimitStatus "Front hitch yaw limit status: Parameter used to report the Tractor ECU's present limit status associated with the front hitch yaw commands. Value Meaning 000 Not limited 001 Operator limited/controlled (request cannot be implemented) 010 Limited High...";
CM_ SG_ 2365293566 FrontHitchYawExitReasonCode "Front hitch yaw exit/reason code: This parameter is used to indicate why the front hitch cannot accept remote yaw commands or has most recently stopped accepting remote commands. Value Meaning 000000 No reason/all clear 000001 Required level of opera...";
CM_ BO_ 2365293822 "Operator Status";
CM_ SG_ 2365293822 OperatorStatusSequenceCounter "Operator Status Sequence Counter: The operator status sequence counter is a counter of the messages transmitted by the transmitting Control Function on the network, not of the time elapsed between the messages, and therefore conveys no information ab...";
CM_ SG_ 2365293822 OperatorPresenceState "Operator Presence state: The Operator presence state SPN is a status indicator for the current state of the operator presence detection system. Operator status recipients may use this information to determine the appropriate system functionality. Val...";
CM_ SG_ 2365293822 OperatorAwarenessState "Operator Awareness state: The operator awareness state SPN is a status indicator for the current state of the operator awareness detection system. Operator status recipients may use this information to determine the appropriate system functionality. ...";
CM_ SG_ 2365293822 OprtrPrsnAndAwrnssSttsChksm "Operator Presence and Awareness Status Checksum: The operator presence and awareness status checksum is the CRC checksum of the first 56 data bits of the operator status message using the CRC-8-CCIT Polynomial (0x07/0xE0/0x83). This CRC is used to ve...";
CM_ BO_ 2566704638 "Drive Strategy Status";
CM_ SG_ 2566704638 DriveStrategyPriority1 "Drive strategy priority 1: This parameter indicates the current tractor drive strategy priority structure, which determines the balance between fuel economy/consumption and the torque reserve of the engine. This parameter indicates the highest priori...";
CM_ SG_ 2566704638 DriveStrategyPriority2 "Drive strategy priority 2: This parameter indicates the current tractor drive strategy priority structure, which determines the balance between fuel economy/consumption and the torque reserve of the engine. This parameter indicates the second highest...";
CM_ SG_ 2566704638 DriveStrategyPriority3 "Drive strategy priority 3: This parameter indicates the current tractor drive strategy priority structure, which determines the balance between fuel economy/consumption and the torque reserve of the engine. This parameter indicates the third highest ...";
CM_ SG_ 2566704638 DriveStrategyPriority4 "Drive strategy priority 4: This parameter indicates the current tractor drive strategy priority structure, which determines the balance between fuel economy/consumption and the torque reserve of the engine. This parameter indicates lowest priority. M...";
CM_ SG_ 2566704638 DriveStrategyRequestState "Drive strategy request state: This parameter reports the tractor's state associated with Drive Strategy requests that are transient/temporary/one-shot. Value Meaning 00 External Request Accepted. No subsequent operator intervention 01 Control overrid...";
CM_ SG_ 2566704638 DriveStrategyExitReasonCode "Drive strategy exit/reason code: This parameter is used to indicate why the drive strategy subsystem cannot currently accept remote commands or has most recently stopped accepting remote commands. Value Meaning 000000 No reason/all clear 000001 Requi...";
CM_ BO_ 2365378302 "Drive Strategy command";
CM_ SG_ 2365378302 DriveStrategyPriority1Request "Drive strategy priority 1 request: This parameter is used to request an alteration to the tractor drive strategy priority structure, which determines the balance between fuel economy/consumption and the torque reserve of the engine. This parameter in...";
CM_ SG_ 2365378302 DriveStrategyPriority2Request "Drive strategy priority 2 request: This parameter is used to request an alteration to the tractor drive strategy priority structure, which determines the balance between fuel economy/consumption and the torque reserve of the engine. This parameter in...";
CM_ SG_ 2365378302 DriveStrategyPriority3Request "Drive strategy priority 3 request: This parameter is used to request an alteration to the tractor drive strategy priority structure, which determines the balance between fuel economy/consumption and the torque reserve of the engine. This parameter in...";
CM_ SG_ 2365378302 DriveStrategyPriority4Request "Drive strategy priority 4 request: This parameter is used to request an alteration to the tractor drive strategy priority structure, which determines the balance between fuel economy/consumption and the torque reserve of the engine. This parameter in...";
CM_ SG_ 2365378302 RstrOprtrDrvStrtgSttngRqst "Restore operator drive strategy setting request: This parameter requests the drive strategy subsystem to restore the settings for drive strategy to the state before automation was ended. Value Meaning 00 No Request (sent when implement does not want ...";
CM_ BO_ 2365391614 "All implements stop operations switch state";
CM_ SG_ 2365391614 StopAllImplementOperations "Stop all implement operations: State of a switch or other operator input to immediately stop operation of all functions that were activated by operator controls or message commands from a VT, auxiliary control input, TECU, task controller or sequence...";
CM_ SG_ 2365391614 StpAllImplmntOprtnsTrnstnNmr "Stop All Implement Operations Transition Number: This parameter indicates the number of transitions from Permit (01) to Stop (00) since power up of the Stop all implement operations parameter. The parameter resets to zero on the next transition after...";
CM_ BO_ 2365391870 "Implement Operating state command";
CM_ SG_ 2365391870 ImplementOperatingStateCommand "Implement operating state command: Command for setting the operating state of a connected implement system. Value Meaning 00 Set implement to field working state 01 Set implement to transport state 10 Set implement to park state 11 Take no action...";
CM_ BO_ 2566730494 "ECU diagnostic protocol";
CM_ SG_ 2566730494 DgnstPrtlIdntftn "Diagnostic protocol identification: This parameter indicates the diagnostic protocols in addition to ISO 11783 that are supported by a control function.Value Meaning00000000 No additional diagnostic protocols supported00000001 J1939–7300000010 ISO 14...";
CM_ BO_ 2566734590 "ISOBUS compliance certification";
CM_ SG_ 2566734590 IssCmplnTstPrtlPltnYr "ISOBUS compliance test protocol publication year: The publication year of the compliance test protocol to which the certification test was performed.";
CM_ SG_ 2566734590 IssCmplnCrtftnLrtrId "ISOBUS compliance certification laboratory ID: Manufacturer code of the laboratory that performed the compliance test. In the case of a self-certified CF, this matches the manufacturer code contained in the address claim PGN. The value of this parame...";
CM_ SG_ 2566734590 IssCmplnCrtftnTpMnmmCf "ISOBUS compliance certification type – Minimum CF: As of the third edition of this document, this parameter has been deprecated due to a change in the definition and communication of functionalities and shall be transmitted as 0. See ISO 11783-12 for...";
CM_ SG_ 2566734590 IssCmplnCrtftnTpTClss1 "ISOBUS compliance certification type – TECU Class 1: As of the third edition of this document, this parameter has been deprecated due to a change in the definition and communication of functionalities and shall be transmitted as 0. See ISO 11783-12 f...";
CM_ SG_ 2566734590 IssCmplnCrtftnTpTClss2 "ISOBUS compliance certification type – TECU Class 2: As of the third edition of this document, this parameter has been deprecated due to a change in the definition and communication of functionalities and shall be transmitted as 0. See ISO 11783-12 f...";
CM_ SG_ 2566734590 IssCmplnCrtftnTpTClss3 "ISOBUS compliance certification type – TECU Class 3: As of the third edition of this document, this parameter has been deprecated due to a change in the definition and communication of functionalities and shall be transmitted as 0. See ISO 11783-12 f...";
CM_ SG_ 2566734590 IssCmplnCrtftnTpClss3E "ISOBUS compliance certification type – Class 3 ECU: As of the third edition of this document, this parameter has been deprecated due to a change in the definition and communication of functionalities and shall be transmitted as 0. See ISO 11783-12 fo...";
CM_ SG_ 2566734590 IssCmplnCrtftnTpVrtlTrmnl "ISOBUS compliance certification type – Virtual terminal: As of the third edition of this document, this parameter has been deprecated due to a change in the definition and communication of functionalities and shall be transmitted as 0. See ISO 11783-...";
CM_ SG_ 2566734590 IssCmplnCrtftnTpVtWrkngStMstr "ISOBUS compliance certification type – VT working set master: As of the third edition of this document, this parameter has been deprecated due to a change in the definition and communication of functionalities and shall be transmitted as 0. See ISO 1...";
CM_ SG_ 2566734590 IssCmplnCrtftnTpVtWrkngStMmr "ISOBUS compliance certification type – VT working set member: As of the third edition of this document, this parameter has been deprecated due to a change in the definition and communication of functionalities and shall be transmitted as 0. See ISO 1...";
CM_ SG_ 2566734590 IssCmplnCrtftnTpTskCntrllr "ISOBUS compliance certification type – Task Controller: As of the third edition of this document, this parameter has been deprecated due to a change in the definition and communication of functionalities and shall be transmitted as 0. See ISO 11783-1...";
CM_ SG_ 2566734590 IssCmplnCrtftnTpTWrkngStMstr "ISOBUS compliance certification type – TC working set master: As of the third edition of this document, this parameter has been deprecated due to a change in the definition and communication of functionalities and shall be transmitted as 0. See ISO 1...";
CM_ SG_ 2566734590 IssCmplnCrtftnTpTWrkngStMmr "ISOBUS compliance certification type – TC working set member: As of the third edition of this document, this parameter has been deprecated due to a change in the definition and communication of functionalities and shall be transmitted as 0. See ISO 1...";
CM_ SG_ 2566734590 IssCmplnCrtftnTpFlSrvr "ISOBUS compliance certification type – File server: As of the third edition of this document, this parameter has been deprecated due to a change in the definition and communication of functionalities and shall be transmitted as 0. See ISO 11783-12 fo...";
CM_ SG_ 2566734590 IssCmplnCrtftnTpGpsRvr "ISOBUS compliance certification type – GPS receiver: As of the third edition of this document, this parameter has been deprecated due to a change in the definition and communication of functionalities and shall be transmitted as 0. See ISO 11783-12 f...";
CM_ SG_ 2566734590 IssCmplnCrtftnRfrnNmr "ISOBUS compliance certification reference number: Certification reference number assigned by a certification laboratory. This value can be used together with the Certification Lab ID and CF Manufacturer ID to uniquely identify the test file of the ce...";
CM_ SG_ 2566734590 IssCmplnCrtftnMssgRvsn "ISOBUS compliance certification message revision: This parameter distinguishes the format of the ISOBUS Compliance Certification message in the second edition from the format in the third and later editions.value / meaning0  format of the message acc...";
CM_ BO_ 2365408254 "Machine Selected Speed command";
CM_ SG_ 2365408254 MhnSltdSpdStPntCmmnd "Machine selected speed set point command: Commanded set point value of the machine speed as measured by the selected source.";
CM_ SG_ 2365408254 MhnSltdSpdStpntLmt "Machine selected speed setpoint limit: This parameter is used by a machine to communicate its maximum allowed speed to the tractor.";
CM_ SG_ 2365408254 MachineSelectedDirectionCommand "Machine selected direction command: Commanded direction of the machine. Value  Meaning 00       Reverse 01       Forward 10       Error indication 11       Not available";
CM_ BO_ 2365458686 "Required Tractor Facilities message";
CM_ SG_ 2365458686 MachineSelectedSpeed "Machine selected speed: This parameter is used to request a facility of a Tractor ECU. Value Meaning 0 Facility not required 1 Facility required";
CM_ SG_ 2365458686 SpeedInformationEngineSpeed "Speed information - engine speed: This parameter is used to request a facility of a Tractor ECU. Value Meaning 0 Facility not required 1 Facility required";
CM_ SG_ 2365458686 SpdInfrmtnGrndBsdSpd1 "Speed information - ground based speed: This parameter is used to request a facility of a Tractor ECU. Value Meaning 0 Facility not required 1 Facility required";
CM_ SG_ 2365458686 SpeedInformationWheelBasedSpeed1 "Speed information - wheel based speed: This parameter is used to request a facility of a Tractor ECU. Value Meaning 0 Facility not required 1 Facility required";
CM_ SG_ 2365458686 PowerManagementMaintainPower "Power management - maintain power: This parameter is used to request a facility of a Tractor ECU. Value Meaning 0 Facility not required 1 Facility required";
CM_ SG_ 2365458686 PwrMngmntMxmmTmTrtrPwr "Power management - maximum time tractor power: This parameter is used to request a facility of a Tractor ECU. Value Meaning 0 Facility not required 1 Facility required";
CM_ SG_ 2365458686 PowerManagementKeySwitch "Power management - key switch: This parameter is used to request a facility of a Tractor ECU. Value Meaning 0 Facility not required 1 Facility required";
CM_ SG_ 2365458686 TractorEcuClassRequest "Tractor ECU class request: This parameter is used to request the class of a Tractor ECU. Data length:2 bits Value Meaning 00 TECU class 1 01 TECU class 2 10 TECU class 3 11 Not requested";
CM_ SG_ 2365458686 LnggCmmndStrgInTrtrE "Language command storage in Tractor ECU: This parameter is used to request a facility of a Tractor ECU. Value Meaning 0 Facility not required 1 Facility required";
CM_ SG_ 2365458686 LghtngMnmlStAsExstngTrlrCnntr "Lighting - minimal set as existing trailer connector: This parameter is used to request a facility of a Tractor ECU. Value Meaning 0 Facility not required 1 Facility required";
CM_ SG_ 2365458686 PtInfrmtnRrShftEnggmnt "PTO information - rear shaft engagement: This parameter is used to request a facility of a Tractor ECU. Value Meaning 0 Facility not required 1 Facility required";
CM_ SG_ 2365458686 PtoInformationRearShaftSpeed "PTO information - rear shaft speed: This parameter is used to request a facility of a Tractor ECU. Value Meaning 0 Facility not required 1 Facility required";
CM_ SG_ 2365458686 HitchInformationRearInWork "Hitch information - rear in work: This parameter is used to request a facility of a Tractor ECU. Value Meaning 0 Facility not required 1 Facility required";
CM_ SG_ 2365458686 HitchInformationRearPosition "Hitch information - rear position: This parameter is used to request a facility of a Tractor ECU. Value Meaning 0 Facility not required 1 Facility required";
CM_ SG_ 2365458686 EstmtdOrMsrdAxlrVlvStts "Estimated or measured auxiliary valve status: This parameter is used to request a facility of a Tractor ECU. Value Meaning 0 Facility not required 1 Facility required";
CM_ SG_ 2365458686 LghtngFllImplmntLghtngMssgSt "Lighting - full implement lighting message set: This parameter is used to request a facility of a Tractor ECU. Value Meaning 0 Facility not required 1 Facility required";
CM_ SG_ 2365458686 AddtnlHthPrmtrsRrDrft "Additional hitch parameters - rear draft: This parameter is used to request a facility of a Tractor ECU. Value Meaning 0 Facility not required 1 Facility required";
CM_ SG_ 2365458686 SpdAndDstnWhlBsdDrtn "Speed and distance - wheel-based direction: This parameter is used to request a facility of a Tractor ECU. Value Meaning 0 Facility not required 1 Facility required";
CM_ SG_ 2365458686 SpdAndDstnWhlBsdDstn "Speed and distance - wheel-based distance: This parameter is used to request a facility of a Tractor ECU. Value Meaning 0 Facility not required 1 Facility required";
CM_ SG_ 2365458686 SpdAndDstnGrndBsdDrtn "Speed and distance - ground-based direction: This parameter is used to request a facility of a Tractor ECU. Value Meaning 0 Facility not required 1 Facility required";
CM_ SG_ 2365458686 SpdAndDstnGrndBsdDstn "Speed and distance - ground-based distance: This parameter is used to request a facility of a Tractor ECU. Value Meaning 0 Facility not required 1 Facility required";
CM_ SG_ 2365458686 TimeDate "Time date: This parameter is used to request a facility of a Tractor ECU. Value Meaning 0 Facility not required 1 Facility required";
CM_ SG_ 2365458686 PtCmmndsRrPtMdGrCmmnd "PTO commands - rear PTO mode/gear command: This parameter is used to request a facility of a Tractor ECU. Value Meaning 0 Facility not required 1 Facility required";
CM_ SG_ 2365458686 LimitRequestStatusReporting "Limit/request status reporting: This parameter indicates whether the requester requires reporting of the limit status and request status parameters in the tractor’s supported status messages. See A.19.11 and A.20.19 for an example of one of these par...";
CM_ SG_ 2365458686 AuxiliaryValveCommands "Auxiliary valve commands: This parameter is used to request a facility of a Tractor ECU. Value Meaning 0 Facility not required 1 Facility required";
CM_ SG_ 2365458686 PtCmmndsRrPtEnggmntCmmnd "PTO commands - rear PTO engagement command: This parameter is used to request a facility of a Tractor ECU. Value Meaning 0 Facility not required 1 Facility required";
CM_ SG_ 2365458686 PtoCommandsRearPtoSpeedCommand "PTO commands - rear PTO speed command: This parameter is used to request a facility of a Tractor ECU. Value Meaning 0 Facility not required 1 Facility required";
CM_ SG_ 2365458686 HitchCommandsRearHitchPosition "Hitch commands - rear hitch position: This parameter is used to request a facility of a Tractor ECU. Value Meaning 0 Facility not required 1 Facility required";
CM_ SG_ 2365458686 DirectionControl "Direction control: This parameter is used to request a facility of a Tractor ECU. Value Meaning 0 Facility not required 1 Facility required";
CM_ SG_ 2365458686 MachineSelectedSpeedControl "Machine selected speed control: This parameter is used to request a facility of a Tractor ECU. Value Meaning 0 Facility not required 1 Facility required";
CM_ SG_ 2365458686 OperatorExternalLightControls "Operator external light controls: This parameter is used to request a facility of a Tractor ECU. Value Meaning 0 Facility not required 1 Facility required";
CM_ SG_ 2365458686 NvgtnlPsdRngNsSttsts "Navigational pseudo-range noise statistics: This parameter is used to request a facility of a Tractor ECU. Value Meaning 0 Facility not required 1 Facility required";
CM_ SG_ 2365458686 NavigationalSystemPositionData "Navigational system position data: This parameter is used to request a facility of a Tractor ECU. Value Meaning 0 Facility not required 1 Facility required";
CM_ SG_ 2365458686 NvgtnlSstmHghOtptPstn "Navigational system high-output position: This parameter is used to request a facility of a Tractor ECU. Value Meaning 0 Facility not required 1 Facility required";
CM_ SG_ 2365458686 PtCmmndsFrntPtEnggmntCmmnd "PTO commands - front PTO engagement command: This parameter is used to request a facility of a Tractor ECU. Value Meaning 0 Facility not required 1 Facility required";
CM_ SG_ 2365458686 PtoCommandsFrontPtoSpeedCommand "PTO commands - front PTO speed command: This parameter is used to request a facility of a Tractor ECU. Value Meaning 0 Facility not required 1 Facility required";
CM_ SG_ 2365458686 HitchCommandsFrontHitchPosition "Hitch commands - front hitch position: This parameter is used to request a facility of a Tractor ECU. Value Meaning 0 Facility not required 1 Facility required";
CM_ SG_ 2365458686 AddtnlHthPrmtrsFrntDrft "Additional hitch parameters - front draft: This parameter is used to request a facility of a Tractor ECU. Value Meaning 0 Facility not required 1 Facility required";
CM_ SG_ 2365458686 PtInfrmtnFrntShftEnggmnt "PTO information - front shaft engagement: This parameter is used to request a facility of a Tractor ECU. Value Meaning 0 Facility not required 1 Facility required";
CM_ SG_ 2365458686 PtoInformationFrontShaftSpeed "PTO information - front shaft speed: This parameter is used to request a facility of a Tractor ECU. Value Meaning 0 Facility not required 1 Facility required";
CM_ SG_ 2365458686 HitchInformationFrontInWork "Hitch information - front in work: This parameter is used to request a facility of a Tractor ECU. Value Meaning 0 Facility not required 1 Facility required";
CM_ SG_ 2365458686 HitchInformationFrontPosition "Hitch information - front position: This parameter is used to request a facility of a Tractor ECU. Value Meaning 0 Facility not required 1 Facility required";
CM_ SG_ 2365458686 DriveStrategyStatusAndCommands "Drive Strategy Status and Commands: This parameter is used to request a facility of a Tractor ECU. Value Meaning 0 Facility not required 1 Facility required";
CM_ SG_ 2365458686 ExtrnlGdnSttsAndCmmnds "External Guidance Status and Commands: This parameter is used to request a facility of a Tractor ECU. Value Meaning 0 Facility not required 1 Facility required";
CM_ SG_ 2365458686 PtCmmndsFrntPtMdGrCmmnd "PTO commands - front PTO mode/gear command: This parameter is used to request a facility of a Tractor ECU. Value Meaning 0 Facility not required 1 Facility required";
CM_ SG_ 2365458686 TrtrFltRsrvdBtIndtr "Tractor facility reserved bit indicator: This parameter indicates whether the reserved bits in the message are set to 0 or 1. Data length:2 bits Value Meaning 0 Reserved bits are set to 0 1 Reserved bits are set to 1";
CM_ BO_ 2365458942 "Tractor Facilities response message";
CM_ SG_ 2365458942 MachineSelectedSpeed "Machine selected speed: This parameter is used to respond to a request for a facility of a Tractor ECU.Value Meaning 0 Facility not available 1 Facility available";
CM_ SG_ 2365458942 SpeedInformationEngineSpeed "Speed information - engine speed: This parameter is used to respond to a request for a facility of a Tractor ECU.Value Meaning 0 Facility not available 1 Facility available";
CM_ SG_ 2365458942 PowerManagementMaintainPower "Power management - maintain power: This parameter is used to respond to a request for a facility of a Tractor ECU.Value Meaning 0 Facility not available 1 Facility available";
CM_ SG_ 2365458942 PwrMngmntMxmmTmTrtrPwr "Power management - maximum time tractor power: This parameter is used to respond to a request for a facility of a Tractor ECU.Value Meaning 0 Facility not available 1 Facility available";
CM_ SG_ 2365458942 PowerManagementKeySwitch "Power management - key switch: This parameter is used to respond to a request for a facility of a Tractor ECU.Value Meaning 0 Facility not available 1 Facility available";
CM_ SG_ 2365458942 LnggCmmndStrgInTrtrE "Language command storage in Tractor ECU: This parameter is used to respond to a request for a facility of a Tractor ECU.Value Meaning 0 Facility not available 1 Facility available";
CM_ SG_ 2365458942 LghtngMnmlStAsExstngTrlrCnntr "Lighting - minimal set as existing trailer connector: This parameter is used to respond to a request for a facility of a Tractor ECU.Value Meaning 0 Facility not available 1 Facility available";
CM_ SG_ 2365458942 PtInfrmtnRrShftEnggmnt "PTO information - rear shaft engagement: This parameter is used to respond to a request for a facility of a Tractor ECU.Value Meaning 0 Facility not available 1 Facility available";
CM_ SG_ 2365458942 PtoInformationRearShaftSpeed "PTO information - rear shaft speed: This parameter is used to respond to a request for a facility of a Tractor ECU.Value Meaning 0 Facility not available 1 Facility available";
CM_ SG_ 2365458942 HitchInformationRearInWork "Hitch information - rear in work: This parameter is used to respond to a request for a facility of a Tractor ECU.Value Meaning 0 Facility not available 1 Facility available";
CM_ SG_ 2365458942 HitchInformationRearPosition "Hitch information - rear position: This parameter is used to respond to a request for a facility of a Tractor ECU.Value Meaning 0 Facility not available 1 Facility available";
CM_ SG_ 2365458942 EstmtdOrMsrdAxlrVlvStts "Estimated or measured auxiliary valve status: This parameter is used to respond to a request for a facility of a Tractor ECU.Value Meaning 0 Facility not available 1 Facility available";
CM_ SG_ 2365458942 LghtngFllImplmntLghtngMssgSt "Lighting - full implement lighting message set: This parameter is used to respond to a request for a facility of a Tractor ECU.Value Meaning 0 Facility not available 1 Facility available";
CM_ SG_ 2365458942 AddtnlHthPrmtrsRrDrft "Additional hitch parameters - rear draft: This parameter is used to respond to a request for a facility of a Tractor ECU.Value Meaning 0 Facility not available 1 Facility available";
CM_ SG_ 2365458942 SpdAndDstnWhlBsdDrtn "Speed and distance - wheel-based direction: This parameter is used to respond to a request for a facility of a Tractor ECU.Value Meaning 0 Facility not available 1 Facility available";
CM_ SG_ 2365458942 SpdAndDstnWhlBsdDstn "Speed and distance - wheel-based distance: This parameter is used to respond to a request for a facility of a Tractor ECU.Value Meaning 0 Facility not available 1 Facility available";
CM_ SG_ 2365458942 SpdAndDstnGrndBsdDrtn "Speed and distance - ground-based direction: This parameter is used to respond to a request for a facility of a Tractor ECU.Value Meaning 0 Facility not available 1 Facility available";
CM_ SG_ 2365458942 SpdAndDstnGrndBsdDstn "Speed and distance - ground-based distance: This parameter is used to respond to a request for a facility of a Tractor ECU.Value Meaning 0 Facility not available 1 Facility available";
CM_ SG_ 2365458942 TimeDate "Time date: This parameter is used to respond to a request for a facility of a Tractor ECU.Value Meaning 0 Facility not available 1 Facility available";
CM_ SG_ 2365458942 PtCmmndsRrPtMdGrCmmnd "PTO commands - rear PTO mode/gear command: This parameter is used to respond to a request for a facility of a Tractor ECU.Value Meaning 0 Facility not available 1 Facility available";
CM_ SG_ 2365458942 AuxiliaryValveCommands "Auxiliary valve commands: This parameter is used to respond to a request for a facility of a Tractor ECU.Value Meaning 0 Facility not available 1 Facility available";
CM_ SG_ 2365458942 PtCmmndsRrPtEnggmntCmmnd "PTO commands - rear PTO engagement command: This parameter is used to respond to a request for a facility of a Tractor ECU.Value Meaning 0 Facility not available 1 Facility available";
CM_ SG_ 2365458942 PtoCommandsRearPtoSpeedCommand "PTO commands - rear PTO speed command: This parameter is used to respond to a request for a facility of a Tractor ECU.Value Meaning 0 Facility not available 1 Facility available";
CM_ SG_ 2365458942 HitchCommandsRearHitchPosition "Hitch commands - rear hitch position: This parameter is used to respond to a request for a facility of a Tractor ECU.Value Meaning 0 Facility not available 1 Facility available";
CM_ SG_ 2365458942 DirectionControl "Direction control: This parameter is used to respond to a request for a facility of a Tractor ECU.Value Meaning 0 Facility not available 1 Facility available";
CM_ SG_ 2365458942 MachineSelectedSpeedControl "Machine selected speed control: This parameter is used to respond to a request for a facility of a Tractor ECU.Value Meaning 0 Facility not available 1 Facility available";
CM_ SG_ 2365458942 OperatorExternalLightControls "Operator external light controls: This parameter is used to respond to a request for a facility of a Tractor ECU.Value Meaning 0 Facility not available 1 Facility available";
CM_ SG_ 2365458942 NvgtnlPsdRngNsSttsts "Navigational pseudo-range noise statistics: This parameter is used to respond to a request for a facility of a Tractor ECU.Value Meaning 0 Facility not available 1 Facility available";
CM_ SG_ 2365458942 NavigationalSystemPositionData "Navigational system position data: This parameter is used to respond to a request for a facility of a Tractor ECU.Value Meaning 0 Facility not available 1 Facility available";
CM_ SG_ 2365458942 NvgtnlSstmHghOtptPstn "Navigational system high-output position: This parameter is used to respond to a request for a facility of a Tractor ECU.Value Meaning 0 Facility not available 1 Facility available";
CM_ SG_ 2365458942 PtCmmndsFrntPtEnggmntCmmnd "PTO commands - front PTO engagement command: This parameter is used to respond to a request for a facility of a Tractor ECU.Value Meaning 0 Facility not available 1 Facility available";
CM_ SG_ 2365458942 PtoCommandsFrontPtoSpeedCommand "PTO commands - front PTO speed command: This parameter is used to respond to a request for a facility of a Tractor ECU.Value Meaning 0 Facility not available 1 Facility available";
CM_ SG_ 2365458942 HitchCommandsFrontHitchPosition "Hitch commands - front hitch position: This parameter is used to respond to a request for a facility of a Tractor ECU.Value Meaning 0 Facility not available 1 Facility available";
CM_ SG_ 2365458942 AddtnlHthPrmtrsFrntDrft "Additional hitch parameters - front draft: This parameter is used to respond to a request for a facility of a Tractor ECU.Value Meaning 0 Facility not available 1 Facility available";
CM_ SG_ 2365458942 PtInfrmtnFrntShftEnggmnt "PTO information - front shaft engagement: This parameter is used to respond to a request for a facility of a Tractor ECU.Value Meaning 0 Facility not available 1 Facility available";
CM_ SG_ 2365458942 PtoInformationFrontShaftSpeed "PTO information - front shaft speed: This parameter is used to respond to a request for a facility of a Tractor ECU.Value Meaning 0 Facility not available 1 Facility available";
CM_ SG_ 2365458942 HitchInformationFrontInWork "Hitch information - front in work: This parameter is used to respond to a request for a facility of a Tractor ECU.Value Meaning 0 Facility not available 1 Facility available";
CM_ SG_ 2365458942 HitchInformationFrontPosition "Hitch information - front position: This parameter is used to respond to a request for a facility of a Tractor ECU.Value Meaning 0 Facility not available 1 Facility available";
CM_ SG_ 2365458942 DriveStrategyStatusAndCommands "Drive Strategy Status and Commands: This parameter is used to respond to a request for a facility of a Tractor ECU.Value Meaning 0 Facility not available 1 Facility available";
CM_ SG_ 2365458942 ExtrnlGdnSttsAndCmmnds "External Guidance Status and Commands: This parameter is used to respond to a request for a facility of a Tractor ECU.Value Meaning 0 Facility not available 1 Facility available";
CM_ SG_ 2365458942 PtCmmndsFrntPtMdGrCmmnd "PTO commands - front PTO mode/gear command: This parameter is used to respond to a request for a facility of a Tractor ECU.Value Meaning 0 Facility not available 1 Facility available";
CM_ SG_ 2365458942 TrtrFltRsrvdBtIndtr "Tractor facility reserved bit indicator: This parameter indicates whether the reserved bits in the message are set to 0 or 1. Value Meaning 0 Reserved bits are set to 0 1 Reserved bits are set to 1";
CM_ SG_ 2365458942 SpdInfrmtnGrndBsdSpd2 "Speed information - ground-based speed: This parameter is used to respond to a request for a facility of a Tractor ECU.Value Meaning 0 Facility not available 1 Facility available";
CM_ SG_ 2365458942 SpeedInformationWheelBasedSpeed2 "Speed information - wheel-based speed: This parameter is used to respond to a request for a facility of a Tractor ECU.Value Meaning 0 Facility not available 1 Facility available";
CM_ SG_ 2365458942 TractorEcuClassResponse "Tractor ECU class response: This parameter is used to respond to a request of the class of a Tractor ECU.Value Meaning 00 TECU class 1 01 TECU class 2 10 TECU class 3 11 Not available";
CM_ SG_ 2365458942 TrtrFltRspnsLmtRqstSttsRprtng "Tractor facility response - Limit/request status reporting: This parameter indicates whether the vehicle supports reporting of the limit status and request status parameters in the tractor’s supported status messages. See SPN 5151 and 5152 for an exa...";
CM_ BO_ 2365459454 "Tractor control mode command";
CM_ SG_ 2365459454 TrtrCntrlMdCmmndNmr1 "Tractor control mode command number 1: Commands from a connected implement, the task controller or the operator using the tractor ECU interface on a virtual terminal (VT), used for setting the optional function control modes of a tractor ECU. These m...";
CM_ SG_ 2365459454 TrtrCntrlMdCmmndNmr2 "Tractor control mode command number 2: Commands from a connected implement, the task controller or the operator using the tractor ECU interface on a virtual terminal (VT), used for setting the optional function control modes of a tractor ECU. These m...";
CM_ BO_ 2633895166 "Working Set Member";
CM_ SG_ 2633895166 NameOfWorkingSetMember "NAME of Working Set Member: This parameter is a NAME with the format specified in ISO 117835 that identifies a member of a working set. This NAME is the same at that which was used by the member when it claimed its associated source address.";
CM_ BO_ 2633895422 "Working Set Master";
CM_ SG_ 2633895422 NumberOfMembersInWorkingSet "Number of Members in Working Set: A particular working set is identified by the NAME of the working set master, which is associated with the source address (SA) of the message containing this parameter. No member (as identified by a specific NAME, no...";
CM_ BO_ 2566786814 "Response for Repetition Rate";
CM_ SG_ 2566786814 PgnOfTheRequest2 "PGN of the request #2: The PGN for which the repetition rate is requested.";
CM_ SG_ 2566786814 RepetitionRate "Repetition rate: The actual value of the repetition rate of the message with the associated PGN.";
CM_ BO_ 2566787070 "Language command";
CM_ SG_ 2566787070 LanguageCode "Language Code: Command sent to all ECUs specifying the operator's desired language of information. ISO 11783 networks shall use the two-letter language codes in accordance with ISO 639. EXAMPLEDutch: nl; French: fr; English: en; German: de.";
CM_ SG_ 2566787070 TimeFormat "Time format: Command sent to all CFs specifying the displayed format of the time.Value Meaning 00 24 h 01 12 h (am/pm) 10 Reserved 11 No action";
CM_ SG_ 2566787070 DecimalSymbol "Decimal symbol: Command sent to all CFs that determines whether a point or a comma will be displayed as the decimal symbol. Value Meaning 00 Comma is used 01 Point is used 10 Reserved 11 No action";
CM_ SG_ 2566787070 DateFormat "Date format: Command sent to all CFs specifying the displayed format of the date. Value Meaning 0 ddmmyyyy 1 ddyyyymm 2 mmyyyydd 3 mmddyyyy 4 yyyymmdd 5 yyyyddmm 6–250 Reserved";
CM_ SG_ 2566787070 MassUnits "Mass units: Command specifying a mass unit. Value Meaning 00 Metric (tonnes, kilograms, ...) 01 Imperial (long tons, pounds, ...) 10 US (short tons, pounds, ...) 11 No action";
CM_ SG_ 2566787070 VolumeUnits "Volume units: Command specifying a volume unit. Value Meaning 00 Metric (litre) 01 Imperial (gallon) 10 US (gallon) 11 No action";
CM_ SG_ 2566787070 AreaUnits "Area units: Command specifying an area unit. Value Meaning 00 Metric (hectares or square metres) 01 Imperial/US (acres or square feet) 10 Reserved 11 No action";
CM_ SG_ 2566787070 DistanceUnits "Distance units: Command specifying a distance unit. Value Meaning 00 Metric (kilometres, metres, ...) 01 Imperial/US (miles, feet, ...) 10 Reserved 11 No action";
CM_ SG_ 2566787070 UnitsSystem "Units system: Command specifying the system to be used for the display of any unit, or a unit other than those specified in  SPNs 2414-2417 and 5194-5196.Value Meaning 00 Metric 01 Imperial 10 US 11 No action";
CM_ SG_ 2566787070 ForceUnits "Force units: Command specifying a force unit. Value Meaning 00 Metric (newtons, ...) 01 Imperial/US (pounds force, ...) 10 Reserved 11 No action";
CM_ SG_ 2566787070 PressureUnits "Pressure units: Command specifying a pressure unit. Value Meaning 00 Metric (kilopascals, pascals, ...) 01 Imperial/US (pounds per square inch, ...) 10 Reserved 11 No action";
CM_ SG_ 2566787070 TemperatureUnits "Temperature units: Command specifying a temperature unit. Value Meaning 00 Metric (degrees Celsius, degrees Kelvin, ...) 01 Imperial/US (degrees Fahrenheit, ...) 10 Reserved 11 No action";
CM_ SG_ 2566787070 CountryCode "Country Code: Command sent to all ECUs specifying the operator's desired language dialect. ISO 11783 networks shall use the alpha-2 country codes in accordance with ISO 3166-1. When both characters are set to all 1’s it indicates that no country code...";
CM_ BO_ 2365460734 "Auxiliary valve 0 estimated flow";
CM_ SG_ 2365460734 AxlrVlv0ExtndPrtEstmtdFlw "Auxiliary valve 0 extend port estimated flow: Value reported by the controller of flow through the extend port of auxiliary valve 0 of a tractor which could be based on the commanded position of the valve. Zero percent indicates no flow, 100 % indica...";
CM_ SG_ 2365460734 AxlrVlv0RtrtPrtEstmtdFlw "Auxiliary valve 0 retract port estimated flow: Value reported by the controller of flow through the retract port of auxiliary valve 0 of a tractor which could be based on the commanded position of the valve. Zero percent indicates no flow, 100 % indi...";
CM_ SG_ 2365460734 AuxiliaryValveNumber0ValveState "Auxiliary valve number 0 valve state: Measured state of the auxiliary valve number 0. A blocked state means that the valve is closed and there is no flow from or to the valve and that the fluid may be under pressure. A floating state means that there...";
CM_ SG_ 2365460734 AuxiliaryValve0FailSafeMode "Auxiliary valve 0 fail safe mode: Measured state of the fail safe mode of auxiliary valve number 0. Value Meaning 00 Block 01 Float 10 Error indication 11 Not available";
CM_ SG_ 2365460734 AxlrVlvNmr0EstmtdFlwLmtStts "Auxiliary valve number 0 estimated flow limit status: This parameter is used to report the Tractor ECU's present estimated flow limit status associated with valve number 0 flow commands that are persistent. Value Meaning 000 Not limited 001 Operator ...";
CM_ SG_ 2365460734 AuxiliaryValve0ExitReasonCode "Auxiliary valve 0 exit/reason code: This parameter is used to indicate why the auxiliary valve 0 cannot accept remote commands or has most recently stopped accepting remote commands. Value Meaning 000000 No reason/all clear 000001 Required level of o...";
CM_ SG_ 2365460734 AxlrVlv0EstmtdFlwHghRsltn "Auxiliary valve 0 estimated flow (high resolution): Value reported by the controller of flow out of an auxiliary valve 0 of a tractor which could be based on the commanded position of the valve. 0 % indicates no flow, 100 % indicates maximum flow out...";
CM_ BO_ 2365460990 "Auxiliary valve 1 estimated flow";
CM_ SG_ 2365460990 AxlrVlvNmr01ExtndPrtEstmtdFlw "Auxiliary valve number 01 extend port estimated flow: Value reported by the flow controller through the extend port of auxiliary valve 14 of a tractor, which could be based on the commanded position of the valve. Zero percent indicates no flow, 100 %...";
CM_ SG_ 2365460990 AxlrVlvNmr01RtrtPrtEstmtdFlw "Auxiliary valve number 01 retract port estimated flow: Value reported by the flow controller through the retract port of auxiliary valve 01 of a tractor, which could be based on the commanded position of the valve. Zero percent indicates no flow, 100...";
CM_ SG_ 2365460990 AxlrVlvNmr01VlvStt "Auxiliary valve number 01 valve state: Measured state of the auxiliary valve number 01. A blocked state means that the valve is closed and there is no flow from or to the valve and that the fluid may be under pressure. A floating state means that the...";
CM_ SG_ 2365460990 AuxiliaryValve01FailSafeMode "Auxiliary valve 01 fail safe mode: Measured state of the fail safe mode of auxiliary valve number 01. Value Meaning 00 Block 01 Float 10 Error indication 11 Not available";
CM_ SG_ 2365460990 AxlrVlvNmr01EstmtdFlwLmtStts "Auxiliary valve number 01 estimated flow limit status: This parameter is used to report the Tractor ECU's present estimated flow limit status associated with valve number 01 flow commands that are persistent. Value Meaning 000 Not limited 001 Operato...";
CM_ SG_ 2365460990 AuxiliaryValve01ExitReasonCode "Auxiliary valve 01 exit/reason code: This parameter is used to indicate why the auxiliary valve 01 cannot accept remote commands or has most recently stopped accepting remote commands. Value Meaning 000000 No reason/all clear 000001 Required level of...";
CM_ SG_ 2365460990 AxlrVlv01EstmtdFlwHghRsltn "Auxiliary valve 01 estimated flow (high resolution): Value reported by the controller of flow out of an auxiliary valve 01 of a tractor which could be based on the commanded position of the valve. If this parameter is “not available” (all 1’s) then o...";
CM_ BO_ 2365461246 "Auxiliary valve 2 estimated flow";
CM_ SG_ 2365461246 AxlrVlvNmr02ExtndPrtEstmtdFlw "Auxiliary valve number 02 extend port estimated flow: Value reported by the flow controller through the extend port of auxiliary valve 02 of a tractor, which could be based on the commanded position of the valve. Zero percent indicates no flow, 100 %...";
CM_ SG_ 2365461246 AxlrVlvNmr02RtrtPrtEstmtdFlw "Auxiliary valve number 02 retract port estimated flow: Value reported by the flow controller through the retract port of auxiliary valve 02 of a tractor, which could be based on the commanded position of the valve. Zero percent indicates no flow, 100...";
CM_ SG_ 2365461246 AxlrVlvNmr02VlvStt "Auxiliary valve number 02 valve state: Measured state of the auxiliary valve number 02. A blocked state means that the valve is closed and there is no flow from or to the valve and that the fluid may be under pressure. A floating state means that the...";
CM_ SG_ 2365461246 AuxiliaryValve02FailSafeMode "Auxiliary valve 02 fail safe mode: Measured state of the fail safe mode of auxiliary valve number 02. Value Meaning 00 Block 01 Float 10 Error indication 11 Not available";
CM_ SG_ 2365461246 AxlrVlvNmr02EstmtdFlwLmtStts "Auxiliary valve number 02 estimated flow limit status: This parameter is used to report the Tractor ECU's present estimated flow limit status associated with valve number 02 flow commands that are persistent. Value Meaning 000 Not limited 001 Operato...";
CM_ SG_ 2365461246 AuxiliaryValve02ExitReasonCode "Auxiliary valve 02 exit/reason code: This parameter is used to indicate why the auxiliary valve 02 cannot accept remote commands or has most recently stopped accepting remote commands. Value Meaning 000000 No reason/all clear 000001 Required level of...";
CM_ SG_ 2365461246 AxlrVlv02EstmtdFlwHghRsltn "Auxiliary valve 02 estimated flow (high resolution): Value reported by the controller of flow out of an auxiliary valve 02 of a tractor which could be based on the commanded position of the valve. If this parameter is “not available” (all 1’s) then o...";
CM_ BO_ 2365461502 "Auxiliary valve 3 estimated flow";
CM_ SG_ 2365461502 AxlrVlvNmr03ExtndPrtEstmtdFlw "Auxiliary valve number 03 extend port estimated flow: Value reported by the flow controller through the extend port of auxiliary valve 03 of a tractor, which could be based on the commanded position of the valve. Zero percent indicates no flow, 100 %...";
CM_ SG_ 2365461502 AxlrVlvNmr03RtrtPrtEstmtdFlw "Auxiliary valve number 03 retract port estimated flow: Value reported by the flow controller through the retract port of auxiliary valve 03 of a tractor, which could be based on the commanded position of the valve. Zero percent indicates no flow, 100...";
CM_ SG_ 2365461502 AxlrVlvNmr03VlvStt "Auxiliary valve number 03 valve state: Measured state of the auxiliary valve number 03. A blocked state means that the valve is closed and there is no flow from or to the valve and that the fluid may be under pressure. A floating state means that the...";
CM_ SG_ 2365461502 AuxiliaryValve03FailSafeMode "Auxiliary valve 03 fail safe mode: Measured state of the fail safe mode of auxiliary valve number 03. Value Meaning 00 Block 01 Float 10 Error indication 11 Not available";
CM_ SG_ 2365461502 AxlrVlvNmr03EstmtdFlwLmtStts "Auxiliary valve number 03 estimated flow limit status: This parameter is used to report the Tractor ECU's present estimated flow limit status associated with valve number 03 flow commands that are persistent. Value Meaning 000 Not limited 001 Operato...";
CM_ SG_ 2365461502 AuxiliaryValve03ExitReasonCode "Auxiliary valve 03 exit/reason code: This parameter is used to indicate why the auxiliary valve 03 cannot accept remote commands or has most recently stopped accepting remote commands. Value Meaning 000000 No reason/all clear 000001 Required level of...";
CM_ SG_ 2365461502 AxlrVlv03EstmtdFlwHghRsltn "Auxiliary valve 03 estimated flow (high resolution): Value reported by the controller of flow out of an auxiliary valve 03 of a tractor which could be based on the commanded position of the valve. If this parameter is “not available” (all 1’s) then o...";
CM_ BO_ 2365461758 "Auxiliary valve 4 estimated flow";
CM_ SG_ 2365461758 AxlrVlvNmr04ExtndPrtEstmtdFlw "Auxiliary valve number 04 extend port estimated flow: Value reported by the flow controller through the extend port of auxiliary valve 04 of a tractor, which could be based on the commanded position of the valve. Zero percent indicates no flow, 100 %...";
CM_ SG_ 2365461758 AxlrVlvNmr04RtrtPrtEstmtdFlw "Auxiliary valve number 04 retract port estimated flow: Value reported by the flow controller through the retract port of auxiliary valve 04 of a tractor, which could be based on the commanded position of the valve. Zero percent indicates no flow, 100...";
CM_ SG_ 2365461758 AxlrVlvNmr04VlvStt "Auxiliary valve number 04 valve state: Measured state of the auxiliary valve number 04. A blocked state means that the valve is closed and there is no flow from or to the valve and that the fluid may be under pressure. A floating state means that the...";
CM_ SG_ 2365461758 AuxiliaryValve04FailSafeMode "Auxiliary valve 04 fail safe mode: Measured state of the fail safe mode of auxiliary valve number 04. Value Meaning 00 Block 01 Float 10 Error indication 11 Not available";
CM_ SG_ 2365461758 AxlrVlvNmr04EstmtdFlwLmtStts "Auxiliary valve number 04 estimated flow limit status: This parameter is used to report the Tractor ECU's present estimated flow limit status associated with valve number 04 flow commands that are persistent. Value Meaning 000 Not limited 001 Operato...";
CM_ SG_ 2365461758 AuxiliaryValve04ExitReasonCode "Auxiliary valve 04 exit/reason code: This parameter is used to indicate why the auxiliary valve 04 cannot accept remote commands or has most recently stopped accepting remote commands. Value Meaning 000000 No reason/all clear 000001 Required level of...";
CM_ SG_ 2365461758 AxlrVlv04EstmtdFlwHghRsltn "Auxiliary valve 04 estimated flow (high resolution): Value reported by the controller of flow out of an auxiliary valve 04 of a tractor which could be based on the commanded position of the valve. If this parameter is “not available” (all 1’s) then o...";
BA_DEF_ SG_  "SPN" INT 0 524287;
BA_DEF_ BO_  "VFrameFormat" ENUM  "StandardCAN","ExtendedCAN","reserved","J1939PG";
BA_DEF_  "DatabaseVersion" STRING ;
BA_DEF_  "BusType" STRING ;
BA_DEF_  "ProtocolType" STRING ;
BA_DEF_  "DatabaseCompiler" STRING ;
BA_DEF_DEF_  "SPN" 0;
BA_DEF_DEF_  "VFrameFormat" "J1939PG";
BA_DEF_DEF_  "DatabaseVersion" "1.2";
BA_DEF_DEF_  "BusType" "";
BA_DEF_DEF_  "ProtocolType" "";
BA_DEF_DEF_  "DatabaseCompiler" "";
BA_ "ProtocolType" "J1939";
BA_ "BusType" "CAN";
BA_ "DatabaseCompiler" "CSS ELECTRONICS (WWW.CSSELECTRONICS.COM)";
BA_ "DatabaseVersion" "1.0.0";
BA_ "SPN" SG_ 2364604414 FrontHitchRollAngle 7790;
BA_ "SPN" SG_ 2364604414 FrontHitchRollLimitStatus 7791;
BA_ "SPN" SG_ 2364604414 FrontHitchRollExitReasonCode 7792;
BA_ "SPN" SG_ 2364604414 FrontHitchPitchAngle 7793;
BA_ "SPN" SG_ 2364604414 FrontHitchPitchLimitStatus 7794;
BA_ "SPN" SG_ 2364604414 FrontHitchPitchExitReasonCode 7795;
BA_ "SPN" SG_ 2364604926 RearHitchRollAngle 7802;
BA_ "SPN" SG_ 2364604926 RearHitchRollLimitStatus 7803;
BA_ "SPN" SG_ 2364604926 RearHitchRollExitReasonCode 7804;
BA_ "SPN" SG_ 2364604926 RearHitchPitchAngle 7805;
BA_ "SPN" SG_ 2364604926 RearHitchPitchLimitStatus 7806;
BA_ "SPN" SG_ 2364604926 RearHitchPitchExitReasonCode 7807;
BA_ "SPN" SG_ 2364605182 RrHthPthSnstvtCmmnd 7811;
BA_ "SPN" SG_ 2364605182 RearHitchRollCommand 7808;
BA_ "SPN" SG_ 2364605182 RearHitchRollSensitivityCommand 7809;
BA_ "SPN" SG_ 2364605182 RearHitchPitchCommand 7810;
BA_ "SPN" SG_ 2365473278 ImplementOemOption1LightCommand 2395;
BA_ "SPN" SG_ 2365473278 ImplementOemOption2LightCommand 2397;
BA_ "SPN" SG_ 2365473278 RotatingBeaconLightCommand 2385;
BA_ "SPN" SG_ 2365473278 TractorFrontFogLightsCommand 2387;
BA_ "SPN" SG_ 2365473278 TrtrFrntHghMntdWrkLghtsCmmnd 2355;
BA_ "SPN" SG_ 2365473278 TrtrFrntLwMntdWrkLghtsCmmnd 2353;
BA_ "SPN" SG_ 2365473278 TrtrUndrsdMntdWrkLghtsCmmnd 2357;
BA_ "SPN" SG_ 2365473278 DaytimeRunningLightsCommand 2403;
BA_ "SPN" SG_ 2365473278 AlternateHeadlightsCommand 2351;
BA_ "SPN" SG_ 2365473278 LowBeamHeadlightsCommand 2349;
BA_ "SPN" SG_ 2365473278 HighBeamHeadlightsCommand 2347;
BA_ "SPN" SG_ 2365473278 RightTurnSignalLightsCommand 2369;
BA_ "SPN" SG_ 2365473278 LeftTurnSignalLightsCommand 2367;
BA_ "SPN" SG_ 2365473278 BackUpLightsAndAlarmHornCommand 2391;
BA_ "SPN" SG_ 2365473278 CentreStopLightsCommand 2375;
BA_ "SPN" SG_ 2365473278 RightStopLightsCommand 2373;
BA_ "SPN" SG_ 2365473278 LeftStopLightsCommand 2371;
BA_ "SPN" SG_ 2365473278 ImplementClearanceLightsCommand 2383;
BA_ "SPN" SG_ 2365473278 TractorClearanceLightsCommand 2381;
BA_ "SPN" SG_ 2365473278 ImplmntMrkrPstnLghtsCmmnd 2379;
BA_ "SPN" SG_ 2365473278 TrtrMrkrPstnLghtsCmmnd 2377;
BA_ "SPN" SG_ 2365473278 RearFogLightsCommand 2389;
BA_ "SPN" SG_ 2365473278 TrtrRrLwMntdWrkLghtsCmmnd 2359;
BA_ "SPN" SG_ 2365473278 TrtrRrHghMntdWrkLghtsCmmnd 2361;
BA_ "SPN" SG_ 2365473278 TrtrSdLwMntdWrkLghtsCmmnd 2363;
BA_ "SPN" SG_ 2365473278 TrtrSdHghMntdWrkLghtsCmmnd 2365;
BA_ "SPN" SG_ 2365473278 ImplmntRghtFrwrdWrkLghtsCmmnd 2406;
BA_ "SPN" SG_ 2365473278 ImplmntLftFrwrdWrkLghtsCmmnd 2597;
BA_ "SPN" SG_ 2365473278 LghtngDtMssgRqstCmmnd 2393;
BA_ "SPN" SG_ 2365473278 ImplmntRghtFngWrkLghtsCmmnd 2401;
BA_ "SPN" SG_ 2365473278 ImplmntLftFngWrkLghtsCmmnd 2399;
BA_ "SPN" SG_ 2365473278 ImplementRearWorkLightsCommand 2405;
BA_ "SPN" SG_ 2550660862 GnrlPrpsVlvLdSnsPrssr 4086;
BA_ "SPN" SG_ 2550660862 GnrlPrpsVlvPltPrssr 4087;
BA_ "SPN" SG_ 2550660862 GnrlPrpsVlvAssmlLdSnsPrssr 4088;
BA_ "SPN" SG_ 2550660862 GnrlPrpsVlvAssmlSpplPrssr 4089;
BA_ "SPN" SG_ 2566655742 RearHitchPitchSensitivity 7813;
BA_ "SPN" SG_ 2566655742 RearHitchRollSensitivity 7812;
BA_ "SPN" SG_ 2566655998 FrontHitchRollSensitivity 7800;
BA_ "SPN" SG_ 2566655998 FrontHitchPitchSensitivity 7801;
BA_ "SPN" SG_ 2566768126 EcuManufacturerName 4304;
BA_ "SPN" SG_ 2566768126 EcuPartNumber 2901;
BA_ "SPN" SG_ 2566768126 EcuSerialNumber 2902;
BA_ "SPN" SG_ 2566768126 EcuLocation 2903;
BA_ "SPN" SG_ 2566768126 EcuType 2904;
BA_ "SPN" SG_ 2566768126 EcuHardwareId 6714;
BA_ "SPN" SG_ 2566799614 ImplementOemOption1Light 2396;
BA_ "SPN" SG_ 2566799614 ImplementOemOption2Light 2398;
BA_ "SPN" SG_ 2566799614 LeftTurnSignalLights 2368;
BA_ "SPN" SG_ 2566799614 RearFogLights 2390;
BA_ "SPN" SG_ 2566799614 RightTurnSignalLights 2370;
BA_ "SPN" SG_ 2566799614 RotatingBeaconLight 2386;
BA_ "SPN" SG_ 2566799614 TractorFrontFogLights 2388;
BA_ "SPN" SG_ 2566799614 TractorRearLowMountedWorkLights 2360;
BA_ "SPN" SG_ 2566799614 TractorSideLowMountedWorkLights 2364;
BA_ "SPN" SG_ 2566799614 TrtrFrntHghMntdWrkLghts 2356;
BA_ "SPN" SG_ 2566799614 TrtrFrntLwMntdWrkLghts 2354;
BA_ "SPN" SG_ 2566799614 TrtrRrHghMntdWrkLghts 2362;
BA_ "SPN" SG_ 2566799614 TrtrSdHghMntdWrkLghts 2366;
BA_ "SPN" SG_ 2566799614 TrtrUndrsdMntdWrkLghts 2358;
BA_ "SPN" SG_ 2566799614 DaytimeRunningLights 2404;
BA_ "SPN" SG_ 2566799614 AlternateHeadlights 2352;
BA_ "SPN" SG_ 2566799614 LowBeamHeadlights 2350;
BA_ "SPN" SG_ 2566799614 HighBeamHeadlights 2348;
BA_ "SPN" SG_ 2566799614 BackUpLightsAndAlarmHorn 2392;
BA_ "SPN" SG_ 2566799614 CenterStopLights 2376;
BA_ "SPN" SG_ 2566799614 RightStopLights 2374;
BA_ "SPN" SG_ 2566799614 LeftStopLights 2372;
BA_ "SPN" SG_ 2566799614 ImplementClearanceLights 2384;
BA_ "SPN" SG_ 2566799614 TractorClearanceLights 2382;
BA_ "SPN" SG_ 2566799614 ImplementMarkerPositionLights 2380;
BA_ "SPN" SG_ 2566799614 TractorMarkerPositionLights 2378;
BA_ "SPN" SG_ 2566799614 ImplementRightForwardWorkLights 2407;
BA_ "SPN" SG_ 2566799614 ImplementLeftForwardWorkLights 2598;
BA_ "SPN" SG_ 2566799614 ImplementRightFacingWorkLights 2402;
BA_ "SPN" SG_ 2566799614 ImplementLeftFacingWorkLights 2400;
BA_ "SPN" SG_ 2566799614 ImplementRearWorkLights 2394;
BA_ "SPN" SG_ 2566839038 NmrOfSftwrIdntftnFlds 965;
BA_ "SPN" SG_ 2566839038 SoftwareIdentification 234;
BA_ "SPN" SG_ 2566842110 Day 962;
BA_ "SPN" SG_ 2566842110 Hours 961;
BA_ "SPN" SG_ 2566842110 LocalHourOffset 1602;
BA_ "SPN" SG_ 2566842110 LocalMinuteOffset 1601;
BA_ "SPN" SG_ 2566842110 Minutes 960;
BA_ "SPN" SG_ 2566842110 Month 963;
BA_ "SPN" SG_ 2566842110 Seconds 959;
BA_ "SPN" SG_ 2566842110 Year 964;
BA_ "SPN" SG_ 2364604670 FrontHitchRollCommand 7796;
BA_ "SPN" SG_ 2364604670 FrntHthRllSnstvtCmmnd 7797;
BA_ "SPN" SG_ 2364604670 FrontHitchPitchCommand 7798;
BA_ "SPN" SG_ 2364604670 FrntHthPthSnstvtCmmnd 7799;
BA_ "SPN" SG_ 2360147710 EstimatedCurvature 5238;
BA_ "SPN" SG_ 2360147710 MechanicalSystemLockout 5243;
BA_ "SPN" SG_ 2360147710 GuidanceSteeringSystemReadiness 5242;
BA_ "SPN" SG_ 2360147710 SteeringInputPositionStatus 5241;
BA_ "SPN" SG_ 2360147710 RequestResetCommandStatus 5240;
BA_ "SPN" SG_ 2360147710 GuidanceLimitStatus 5726;
BA_ "SPN" SG_ 2360147710 GdnSstmCmmndExtRsnCd 5725;
BA_ "SPN" SG_ 2360147710 GdnSstmRmtEnggSwthStts 9726;
BA_ "SPN" SG_ 2360213246 CurvatureCommand 5237;
BA_ "SPN" SG_ 2360213246 CurvatureCommandStatus 5239;
BA_ "SPN" SG_ 2361720574 GnrlPrpsVlvPrtFlwCmmnd 2944;
BA_ "SPN" SG_ 2361720574 GeneralPurposeValveStateCommand 2933;
BA_ "SPN" SG_ 2361720574 GnrlPrpsVlFlSfMdCmmnd 2935;
BA_ "SPN" SG_ 2361720574 GPpsVvPtFwExtddRstCd 9727;
BA_ "SPN" SG_ 2361786110 GnrlPrpsVlvExtndPrtMsrdFlw 2937;
BA_ "SPN" SG_ 2361786110 GnrlPrpsVlvRtrtPrtMsrdFlw 2938;
BA_ "SPN" SG_ 2361786110 GnrlPrpsVlvExtndPrtPrssr 2941;
BA_ "SPN" SG_ 2361786110 GnrlPrpsVlvRtrtPrtPrssr 2942;
BA_ "SPN" SG_ 2361786110 GnrlPrpsVlvRtrnPrtPrssr 2943;
BA_ "SPN" SG_ 2361786110 GnrlPrpsVlvMsrdLmtStts 5192;
BA_ "SPN" SG_ 2361851646 GnrlPrpsVlvExtndPrtEstmtdFlw 2939;
BA_ "SPN" SG_ 2361851646 GnrlPrpsVlvRtrtPrtEstmtdFlw 2940;
BA_ "SPN" SG_ 2361851646 GeneralPurposeValveState 2932;
BA_ "SPN" SG_ 2361851646 GeneralPurposeValveFailSafeMode 2934;
BA_ "SPN" SG_ 2361851646 GnrlPrpsVlvEstmtdLmtStts 5193;
BA_ "SPN" SG_ 2361851646 GnrlPrpsVlvExtRsnCd 9730;
BA_ "SPN" SG_ 2361851646 GPpsVvExtdPtHRstEsttdFw 9728;
BA_ "SPN" SG_ 2361851646 GPpsVvRttPtHRstEsttdFw 9729;
BA_ "SPN" SG_ 2563571454 PgnOfTheRequest1 21848;
BA_ "SPN" SG_ 2563571454 RepetitionRateCommand 2418;
BA_ "SPN" SG_ 2362507006 BkgrndIllmntnLvlCmmnd 1487;
BA_ "SPN" SG_ 2364547838 MachineSelectedDirection 4309;
BA_ "SPN" SG_ 2364547838 MachineSelectedSpeedSource 4308;
BA_ "SPN" SG_ 2364547838 MachineSelectedSpeedLimitStatus 4307;
BA_ "SPN" SG_ 2364547838 MhnSltdSpdExtRsnCd 5818;
BA_ "SPN" SG_ 2364547838 MachineSelectedSpeed 4305;
BA_ "SPN" SG_ 2364547838 MachineSelectedDistance 4306;
BA_ "SPN" SG_ 2364597502 HeartbeatSequenceNumber 7345;
BA_ "SPN" SG_ 2364620542 FrontHitchYawCommand 9719;
BA_ "SPN" SG_ 2364620798 RearHitchYawCommand 9725;
BA_ "SPN" SG_ 2365293310 RearHitchYawAngle 9720;
BA_ "SPN" SG_ 2365293310 RearHitchYawAngleReferenceFrame 9721;
BA_ "SPN" SG_ 2365293310 RrHthYwAnglAtlCntrlMd 9722;
BA_ "SPN" SG_ 2365293310 RearHitchYawLimitStatus 9723;
BA_ "SPN" SG_ 2365293310 RearHitchYawExitReasonCode 9724;
BA_ "SPN" SG_ 2365293566 FrontHitchYawAngle 9714;
BA_ "SPN" SG_ 2365293566 FrntHthYwAnglRfrnFrm 9715;
BA_ "SPN" SG_ 2365293566 FrntHthYwAnglAtlCntrlMd 9716;
BA_ "SPN" SG_ 2365293566 FrontHitchYawLimitStatus 9717;
BA_ "SPN" SG_ 2365293566 FrontHitchYawExitReasonCode 9718;
BA_ "SPN" SG_ 2365293822 OperatorStatusSequenceCounter 5141;
BA_ "SPN" SG_ 2365293822 OperatorPresenceState 9711;
BA_ "SPN" SG_ 2365293822 OperatorAwarenessState 9712;
BA_ "SPN" SG_ 2365293822 OprtrPrsnAndAwrnssSttsChksm 9713;
BA_ "SPN" SG_ 2566704638 DriveStrategyPriority1 5727;
BA_ "SPN" SG_ 2566704638 DriveStrategyPriority2 5728;
BA_ "SPN" SG_ 2566704638 DriveStrategyPriority3 5729;
BA_ "SPN" SG_ 2566704638 DriveStrategyPriority4 5730;
BA_ "SPN" SG_ 2566704638 DriveStrategyRequestState 5731;
BA_ "SPN" SG_ 2566704638 DriveStrategyExitReasonCode 5732;
BA_ "SPN" SG_ 2365378302 DriveStrategyPriority1Request 5733;
BA_ "SPN" SG_ 2365378302 DriveStrategyPriority2Request 5734;
BA_ "SPN" SG_ 2365378302 DriveStrategyPriority3Request 5735;
BA_ "SPN" SG_ 2365378302 DriveStrategyPriority4Request 5736;
BA_ "SPN" SG_ 2365378302 RstrOprtrDrvStrtgSttngRqst 5737;
BA_ "SPN" SG_ 2365391614 StopAllImplementOperations 5140;
BA_ "SPN" SG_ 2365391614 StpAllImplmntOprtnsTrnstnNmr 7443;
BA_ "SPN" SG_ 2365391870 ImplementOperatingStateCommand 5139;
BA_ "SPN" SG_ 2566730494 DgnstPrtlIdntftn 21854;
BA_ "SPN" SG_ 2566734590 IssCmplnTstPrtlPltnYr 4313;
BA_ "SPN" SG_ 2566734590 IssCmplnCrtftnLrtrId 4316;
BA_ "SPN" SG_ 2566734590 IssCmplnCrtftnTpMnmmCf 4317;
BA_ "SPN" SG_ 2566734590 IssCmplnCrtftnTpTClss1 4318;
BA_ "SPN" SG_ 2566734590 IssCmplnCrtftnTpTClss2 4319;
BA_ "SPN" SG_ 2566734590 IssCmplnCrtftnTpTClss3 4320;
BA_ "SPN" SG_ 2566734590 IssCmplnCrtftnTpClss3E 4321;
BA_ "SPN" SG_ 2566734590 IssCmplnCrtftnTpVrtlTrmnl 4322;
BA_ "SPN" SG_ 2566734590 IssCmplnCrtftnTpVtWrkngStMstr 4323;
BA_ "SPN" SG_ 2566734590 IssCmplnCrtftnTpVtWrkngStMmr 4324;
BA_ "SPN" SG_ 2566734590 IssCmplnCrtftnTpTskCntrllr 4325;
BA_ "SPN" SG_ 2566734590 IssCmplnCrtftnTpTWrkngStMstr 4326;
BA_ "SPN" SG_ 2566734590 IssCmplnCrtftnTpTWrkngStMmr 4327;
BA_ "SPN" SG_ 2566734590 IssCmplnCrtftnTpFlSrvr 4328;
BA_ "SPN" SG_ 2566734590 IssCmplnCrtftnTpGpsRvr 4329;
BA_ "SPN" SG_ 2566734590 IssCmplnCrtftnRfrnNmr 4330;
BA_ "SPN" SG_ 2566734590 IssCmplnCrtftnMssgRvsn 7446;
BA_ "SPN" SG_ 2365408254 MhnSltdSpdStPntCmmnd 4310;
BA_ "SPN" SG_ 2365408254 MhnSltdSpdStpntLmt 4311;
BA_ "SPN" SG_ 2365408254 MachineSelectedDirectionCommand 4312;
BA_ "SPN" SG_ 2365458686 MachineSelectedSpeed 5233;
BA_ "SPN" SG_ 2365458686 SpeedInformationEngineSpeed 5233;
BA_ "SPN" SG_ 2365458686 SpdInfrmtnGrndBsdSpd1 5233;
BA_ "SPN" SG_ 2365458686 SpeedInformationWheelBasedSpeed1 5233;
BA_ "SPN" SG_ 2365458686 PowerManagementMaintainPower 5233;
BA_ "SPN" SG_ 2365458686 PwrMngmntMxmmTmTrtrPwr 5233;
BA_ "SPN" SG_ 2365458686 PowerManagementKeySwitch 5233;
BA_ "SPN" SG_ 2365458686 TractorEcuClassRequest 5232;
BA_ "SPN" SG_ 2365458686 LnggCmmndStrgInTrtrE 5233;
BA_ "SPN" SG_ 2365458686 LghtngMnmlStAsExstngTrlrCnntr 5233;
BA_ "SPN" SG_ 2365458686 PtInfrmtnRrShftEnggmnt 5233;
BA_ "SPN" SG_ 2365458686 PtoInformationRearShaftSpeed 5233;
BA_ "SPN" SG_ 2365458686 HitchInformationRearInWork 5233;
BA_ "SPN" SG_ 2365458686 HitchInformationRearPosition 5233;
BA_ "SPN" SG_ 2365458686 EstmtdOrMsrdAxlrVlvStts 5233;
BA_ "SPN" SG_ 2365458686 LghtngFllImplmntLghtngMssgSt 5233;
BA_ "SPN" SG_ 2365458686 AddtnlHthPrmtrsRrDrft 5233;
BA_ "SPN" SG_ 2365458686 SpdAndDstnWhlBsdDrtn 5233;
BA_ "SPN" SG_ 2365458686 SpdAndDstnWhlBsdDstn 5233;
BA_ "SPN" SG_ 2365458686 SpdAndDstnGrndBsdDrtn 5233;
BA_ "SPN" SG_ 2365458686 SpdAndDstnGrndBsdDstn 5233;
BA_ "SPN" SG_ 2365458686 TimeDate 5233;
BA_ "SPN" SG_ 2365458686 PtCmmndsRrPtMdGrCmmnd 5233;
BA_ "SPN" SG_ 2365458686 LimitRequestStatusReporting 7445;
BA_ "SPN" SG_ 2365458686 AuxiliaryValveCommands 5233;
BA_ "SPN" SG_ 2365458686 PtCmmndsRrPtEnggmntCmmnd 5233;
BA_ "SPN" SG_ 2365458686 PtoCommandsRearPtoSpeedCommand 5233;
BA_ "SPN" SG_ 2365458686 HitchCommandsRearHitchPosition 5233;
BA_ "SPN" SG_ 2365458686 DirectionControl 5233;
BA_ "SPN" SG_ 2365458686 MachineSelectedSpeedControl 5233;
BA_ "SPN" SG_ 2365458686 OperatorExternalLightControls 5233;
BA_ "SPN" SG_ 2365458686 NvgtnlPsdRngNsSttsts 5233;
BA_ "SPN" SG_ 2365458686 NavigationalSystemPositionData 5233;
BA_ "SPN" SG_ 2365458686 NvgtnlSstmHghOtptPstn 5233;
BA_ "SPN" SG_ 2365458686 PtCmmndsFrntPtEnggmntCmmnd 5233;
BA_ "SPN" SG_ 2365458686 PtoCommandsFrontPtoSpeedCommand 5233;
BA_ "SPN" SG_ 2365458686 HitchCommandsFrontHitchPosition 5233;
BA_ "SPN" SG_ 2365458686 AddtnlHthPrmtrsFrntDrft 5233;
BA_ "SPN" SG_ 2365458686 PtInfrmtnFrntShftEnggmnt 5233;
BA_ "SPN" SG_ 2365458686 PtoInformationFrontShaftSpeed 5233;
BA_ "SPN" SG_ 2365458686 HitchInformationFrontInWork 5233;
BA_ "SPN" SG_ 2365458686 HitchInformationFrontPosition 5233;
BA_ "SPN" SG_ 2365458686 DriveStrategyStatusAndCommands 5233;
BA_ "SPN" SG_ 2365458686 ExtrnlGdnSttsAndCmmnds 5233;
BA_ "SPN" SG_ 2365458686 PtCmmndsFrntPtMdGrCmmnd 5233;
BA_ "SPN" SG_ 2365458686 TrtrFltRsrvdBtIndtr 5236;
BA_ "SPN" SG_ 2365458942 MachineSelectedSpeed 5235;
BA_ "SPN" SG_ 2365458942 SpeedInformationEngineSpeed 5235;
BA_ "SPN" SG_ 2365458942 PowerManagementMaintainPower 5235;
BA_ "SPN" SG_ 2365458942 PwrMngmntMxmmTmTrtrPwr 5235;
BA_ "SPN" SG_ 2365458942 PowerManagementKeySwitch 5235;
BA_ "SPN" SG_ 2365458942 LnggCmmndStrgInTrtrE 5235;
BA_ "SPN" SG_ 2365458942 LghtngMnmlStAsExstngTrlrCnntr 5235;
BA_ "SPN" SG_ 2365458942 PtInfrmtnRrShftEnggmnt 5235;
BA_ "SPN" SG_ 2365458942 PtoInformationRearShaftSpeed 5235;
BA_ "SPN" SG_ 2365458942 HitchInformationRearInWork 5235;
BA_ "SPN" SG_ 2365458942 HitchInformationRearPosition 5235;
BA_ "SPN" SG_ 2365458942 EstmtdOrMsrdAxlrVlvStts 5235;
BA_ "SPN" SG_ 2365458942 LghtngFllImplmntLghtngMssgSt 5235;
BA_ "SPN" SG_ 2365458942 AddtnlHthPrmtrsRrDrft 5235;
BA_ "SPN" SG_ 2365458942 SpdAndDstnWhlBsdDrtn 5235;
BA_ "SPN" SG_ 2365458942 SpdAndDstnWhlBsdDstn 5235;
BA_ "SPN" SG_ 2365458942 SpdAndDstnGrndBsdDrtn 5235;
BA_ "SPN" SG_ 2365458942 SpdAndDstnGrndBsdDstn 5235;
BA_ "SPN" SG_ 2365458942 TimeDate 5235;
BA_ "SPN" SG_ 2365458942 PtCmmndsRrPtMdGrCmmnd 5235;
BA_ "SPN" SG_ 2365458942 AuxiliaryValveCommands 5235;
BA_ "SPN" SG_ 2365458942 PtCmmndsRrPtEnggmntCmmnd 5235;
BA_ "SPN" SG_ 2365458942 PtoCommandsRearPtoSpeedCommand 5235;
BA_ "SPN" SG_ 2365458942 HitchCommandsRearHitchPosition 5235;
BA_ "SPN" SG_ 2365458942 DirectionControl 5235;
BA_ "SPN" SG_ 2365458942 MachineSelectedSpeedControl 5235;
BA_ "SPN" SG_ 2365458942 OperatorExternalLightControls 5235;
BA_ "SPN" SG_ 2365458942 NvgtnlPsdRngNsSttsts 5235;
BA_ "SPN" SG_ 2365458942 NavigationalSystemPositionData 5235;
BA_ "SPN" SG_ 2365458942 NvgtnlSstmHghOtptPstn 5235;
BA_ "SPN" SG_ 2365458942 PtCmmndsFrntPtEnggmntCmmnd 5235;
BA_ "SPN" SG_ 2365458942 PtoCommandsFrontPtoSpeedCommand 5235;
BA_ "SPN" SG_ 2365458942 HitchCommandsFrontHitchPosition 5235;
BA_ "SPN" SG_ 2365458942 AddtnlHthPrmtrsFrntDrft 5235;
BA_ "SPN" SG_ 2365458942 PtInfrmtnFrntShftEnggmnt 5235;
BA_ "SPN" SG_ 2365458942 PtoInformationFrontShaftSpeed 5235;
BA_ "SPN" SG_ 2365458942 HitchInformationFrontInWork 5235;
BA_ "SPN" SG_ 2365458942 HitchInformationFrontPosition 5235;
BA_ "SPN" SG_ 2365458942 DriveStrategyStatusAndCommands 5235;
BA_ "SPN" SG_ 2365458942 ExtrnlGdnSttsAndCmmnds 5235;
BA_ "SPN" SG_ 2365458942 PtCmmndsFrntPtMdGrCmmnd 5235;
BA_ "SPN" SG_ 2365458942 TrtrFltRsrvdBtIndtr 5236;
BA_ "SPN" SG_ 2365458942 SpdInfrmtnGrndBsdSpd2 5235;
BA_ "SPN" SG_ 2365458942 SpeedInformationWheelBasedSpeed2 5235;
BA_ "SPN" SG_ 2365458942 TractorEcuClassResponse 5234;
BA_ "SPN" SG_ 2365458942 TrtrFltRspnsLmtRqstSttsRprtng 7444;
BA_ "SPN" SG_ 2365459454 TrtrCntrlMdCmmndNmr1 5204;
BA_ "SPN" SG_ 2365459454 TrtrCntrlMdCmmndNmr2 5204;
BA_ "SPN" SG_ 2633895166 NameOfWorkingSetMember 2845;
BA_ "SPN" SG_ 2633895422 NumberOfMembersInWorkingSet 2409;
BA_ "SPN" SG_ 2566786814 PgnOfTheRequest2 21855;
BA_ "SPN" SG_ 2566786814 RepetitionRate 5198;
BA_ "SPN" SG_ 2566787070 LanguageCode 2410;
BA_ "SPN" SG_ 2566787070 TimeFormat 2413;
BA_ "SPN" SG_ 2566787070 DecimalSymbol 2411;
BA_ "SPN" SG_ 2566787070 DateFormat 2412;
BA_ "SPN" SG_ 2566787070 MassUnits 2417;
BA_ "SPN" SG_ 2566787070 VolumeUnits 2416;
BA_ "SPN" SG_ 2566787070 AreaUnits 2415;
BA_ "SPN" SG_ 2566787070 DistanceUnits 2414;
BA_ "SPN" SG_ 2566787070 UnitsSystem 5197;
BA_ "SPN" SG_ 2566787070 ForceUnits 5196;
BA_ "SPN" SG_ 2566787070 PressureUnits 5195;
BA_ "SPN" SG_ 2566787070 TemperatureUnits 5194;
BA_ "SPN" SG_ 2566787070 CountryCode 9731;
BA_ "SPN" SG_ 2365460734 AxlrVlv0ExtndPrtEstmtdFlw 1901;
BA_ "SPN" SG_ 2365460734 AxlrVlv0RtrtPrtEstmtdFlw 1902;
BA_ "SPN" SG_ 2365460734 AuxiliaryValveNumber0ValveState 1903;
BA_ "SPN" SG_ 2365460734 AuxiliaryValve0FailSafeMode 1910;
BA_ "SPN" SG_ 2365460734 AxlrVlvNmr0EstmtdFlwLmtStts 5161;
BA_ "SPN" SG_ 2365460734 AuxiliaryValve0ExitReasonCode 5800;
BA_ "SPN" SG_ 2365460734 AxlrVlv0EstmtdFlwHghRsltn 9732;
BA_ "SPN" SG_ 2365460990 AxlrVlvNmr01ExtndPrtEstmtdFlw 1913;
BA_ "SPN" SG_ 2365460990 AxlrVlvNmr01RtrtPrtEstmtdFlw 1914;
BA_ "SPN" SG_ 2365460990 AxlrVlvNmr01VlvStt 1915;
BA_ "SPN" SG_ 2365460990 AuxiliaryValve01FailSafeMode 1922;
BA_ "SPN" SG_ 2365460990 AxlrVlvNmr01EstmtdFlwLmtStts 5163;
BA_ "SPN" SG_ 2365460990 AuxiliaryValve01ExitReasonCode 5801;
BA_ "SPN" SG_ 2365460990 AxlrVlv01EstmtdFlwHghRsltn 9733;
BA_ "SPN" SG_ 2365461246 AxlrVlvNmr02ExtndPrtEstmtdFlw 1925;
BA_ "SPN" SG_ 2365461246 AxlrVlvNmr02RtrtPrtEstmtdFlw 1926;
BA_ "SPN" SG_ 2365461246 AxlrVlvNmr02VlvStt 1927;
BA_ "SPN" SG_ 2365461246 AuxiliaryValve02FailSafeMode 1934;
BA_ "SPN" SG_ 2365461246 AxlrVlvNmr02EstmtdFlwLmtStts 5165;
BA_ "SPN" SG_ 2365461246 AuxiliaryValve02ExitReasonCode 5802;
BA_ "SPN" SG_ 2365461246 AxlrVlv02EstmtdFlwHghRsltn 9734;
BA_ "SPN" SG_ 2365461502 AxlrVlvNmr03ExtndPrtEstmtdFlw 1937;
BA_ "SPN" SG_ 2365461502 AxlrVlvNmr03RtrtPrtEstmtdFlw 1938;
BA_ "SPN" SG_ 2365461502 AxlrVlvNmr03VlvStt 1939;
BA_ "SPN" SG_ 2365461502 AuxiliaryValve03FailSafeMode 1946;
BA_ "SPN" SG_ 2365461502 AxlrVlvNmr03EstmtdFlwLmtStts 5167;
BA_ "SPN" SG_ 2365461502 AuxiliaryValve03ExitReasonCode 5803;
BA_ "SPN" SG_ 2365461502 AxlrVlv03EstmtdFlwHghRsltn 9735;
BA_ "SPN" SG_ 2365461758 AxlrVlvNmr04ExtndPrtEstmtdFlw 1949;
BA_ "SPN" SG_ 2365461758 AxlrVlvNmr04RtrtPrtEstmtdFlw 1950;
BA_ "SPN" SG_ 2365461758 AxlrVlvNmr04VlvStt 1951;
BA_ "SPN" SG_ 2365461758 AuxiliaryValve04FailSafeMode 1958;
BA_ "SPN" SG_ 2365461758 AxlrVlvNmr04EstmtdFlwLmtStts 5169;
BA_ "SPN" SG_ 2365461758 AuxiliaryValve04ExitReasonCode 5804;
BA_ "SPN" SG_ 2365461758 AxlrVlv04EstmtdFlwHghRsltn 9736;
